VERSION "1.0.x-173216:1"

NS_ :

BS_:

BU_: PropulsionBatteryCharger iBooster TCM HCU STEERING_CONTROLLER BMS Traction_Motor_Controller
VAL_TABLE_ BCH1_PWR_LINE_State 3 "Not_Available" 2 "Error" 1 "Connected" 0 "Disconnected" ;
VAL_TABLE_ BCH1_ChargerState 3 "Disabled" 2 "Stand_by" 1 "Charging" 0 "Battery Disconnected" ;
VAL_TABLE_ Sendyne_Data 128 "Temperature_mC" 98 "Voltage_2_V" 97 "Voltage_1_V" 96 "Voltage_0_V" 65 "Coulomb_Count_High" 64 "Coulomb_Count_Low" 32 "Current_A" ;
VAL_TABLE_ BMS_Fault_State 1 "Active" 0 "- - - - - -" ;
VAL_TABLE_ BMS_MODE 2 "DRIVE" 1 "CHARGE" 0 "IDLE" ;

BO_ 3221225472 VECTOR__INDEPENDENT_SIG_MSG: 0 Vector__XXX
 SG_ BatteryOverVoltageAlarm : 0|1@1+ (1,0) [0|1] "" Vector__XXX
 SG_ WATT_pEPCU_2_Check_Sequence : 0|8@1+ (1,0) [0|255] "" Vector__XXX
 SG_ WATT_pEPCU_2_Var_4 : 0|16@1+ (0.1,-32768) [-32768|31488] "RPM" Vector__XXX
 SG_ WATT_pEPCU_2_Var_3 : 0|16@1+ (0.1,-3276.8) [-3276.8|3148.7] "Nm" Vector__XXX
 SG_ WATT_pEPCU_2_Var_2 : 0|16@1+ (0.1,-3276.8) [-3276.8|3148.7] "Nm" Vector__XXX
 SG_ WATT_pEPCU_2_Var_1 : 0|4@1+ (1,0) [0|15] "" Vector__XXX
 SG_ WATT_pEPCU_2_cntrl : 0|4@1+ (1,0) [0|15] "" Vector__XXX
 SG_ Min_Cell_Voltage : 0|16@1+ (0.001,0) [0|65.535] "V" Vector__XXX
 SG_ Min_Cell_Voltage : 0|16@1+ (0.001,0) [0|65.535] "V" Vector__XXX
 SG_ New_Signal_1897 : 0|8@1+ (1,0) [0|0] "" Vector__XXX

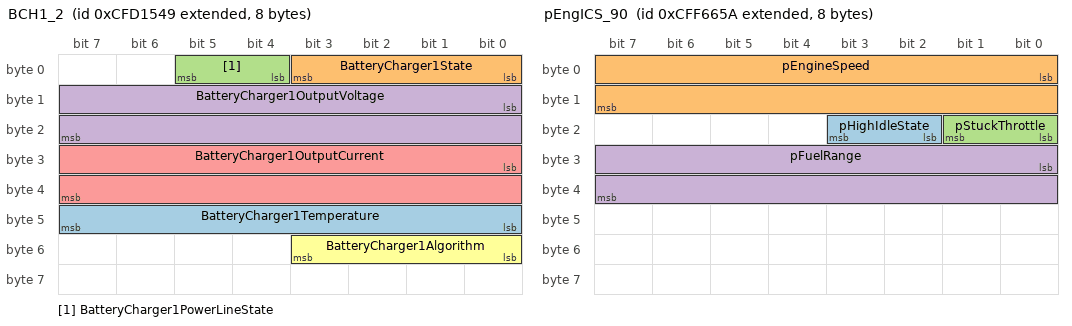
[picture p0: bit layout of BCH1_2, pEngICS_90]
BO_ 2365396297 BCH1_2: 8 Vector__XXX
 SG_ BatteryCharger1Temperature : 40|8@1+ (1,-40) [-40|210] "C" Vector__XXX
 SG_ BatteryCharger1State : 0|4@1+ (1,0) [0|15] "" Vector__XXX
 SG_ BatteryCharger1PowerLineState : 4|2@1+ (1,0) [0|3] "" Vector__XXX
 SG_ BatteryCharger1OutputVoltage : 8|16@1+ (0.05,0) [0|3212.75] "V" Vector__XXX
 SG_ BatteryCharger1OutputCurrent : 24|16@1+ (0.05,-1600) [-1600|1612.75] "A" Vector__XXX
 SG_ BatteryCharger1Algorithm : 48|4@1+ (1,0) [0|15] "" Vector__XXX

BO_ 2316304912 Sendyne_Data: 8 Vector__XXX
 SG_ Sendyne_Type : 0|8@1+ (1,0) [0|255] "" Vector__XXX
 SG_ Sendyne_Data : 15|32@0+ (1E-006,0) [0|4294.967295] "" Vector__XXX

BO_ 2316304913 Sendyne_Request: 1 Vector__XXX
 SG_ Sendyne_Type : 0|8@1+ (1,0) [0|255] "" Vector__XXX

BO_ 2147483941 Traction_Mtr_Ctl_125: 8 Traction_Motor_Controller
 SG_ Torque_Actual_MCU : 16|16@1+ (0.0625,0) [0|4095.9375] "Nm" Vector__XXX
 SG_ Max_Pwr_Lmt_Torque_MCU : 32|16@1+ (0.0625,0) [0|4095.9375] "Nm" Vector__XXX
 SG_ Capacitor_Voltage_MCU : 48|16@1+ (0.0625,0) [0|4095.9375] "V" Vector__XXX

BO_ 2147483940 Traction_Mtr_Ctl_124: 7 Traction_Motor_Controller
 SG_ Stator_Current_MCU : 40|16@1+ (1,0) [0|65535] "A" Vector__XXX
 SG_ Input_Current_MCU : 24|16@1+ (0.0625,0) [0|4095.9375] "A" Vector__XXX

BO_ 2365548122 pEngICS_90: 8 HCU
 SG_ pHighIdleState : 18|2@1+ (1,0) [0|3] "" Vector__XXX
 SG_ pEngineSpeed : 0|16@1+ (1,0) [0|64255] "rpm" Vector__XXX
 SG_ pStuckThrottle : 16|2@1+ (1,0) [0|3] "" Vector__XXX
 SG_ pFuelRange : 24|16@1+ (1,0) [0|64255] "km" Vector__XXX

BO_ 2565866330 EEC2_90: 8 HCU
 SG_ AccelPedalPosition1 : 8|8@1+ (0.4,0) [0|100] "%" Vector__XXX

BO_ 2566889562 BWDevelopmentPGN0_90: 8 HCU
 SG_ pHybridPowertrainSubmode : 2|3@1+ (1,0) [0|0] "1" Vector__XXX
 SG_ pEStopStatus : 0|2@1+ (1,0) [0|0] "1" Vector__XXX

BO_ 2633984602 pDriveSystemStatus_90: 8 HCU
 SG_ pHeatedGripEnable : 48|2@1+ (1,0) [0|3] "" Vector__XXX
 SG_ pSideStandStatus : 36|2@1+ (1,0) [0|3] "" Vector__XXX
 SG_ pTetherSwitchStatus : 46|2@1+ (1,0) [0|3] "" Vector__XXX
 SG_ pLowFuelIndicatorStatus : 10|2@1+ (1,0) [0|3] "" Vector__XXX
 SG_ pOperatorNotInOperatingStation : 38|2@1+ (1,0) [0|3] "" Vector__XXX
 SG_ pParkBrakeIndicatorStatus : 40|3@1+ (1,0) [0|7] "" Vector__XXX
 SG_ pADCRequested : 34|2@1+ (1,0) [0|3] "" Vector__XXX
 SG_ pAWDModeRequested : 32|2@1+ (1,0) [0|3] "" Vector__XXX
 SG_ pRWDModeRequested : 30|2@1+ (1,0) [0|3] "" Vector__XXX
 SG_ pTurfModeRequested : 28|2@1+ (1,0) [0|3] "" Vector__XXX
 SG_ pADCStatus : 0|2@1+ (1,0) [0|3] "" Vector__XXX
 SG_ pTreadleNeutralStatus : 2|2@1+ (1,0) [0|3] "" Vector__XXX
 SG_ pTreadleReverseStatus : 4|2@1+ (1,0) [0|3] "" Vector__XXX
 SG_ pSecurityLightStatus : 6|2@1+ (1,0) [0|3] "" Vector__XXX
 SG_ pHighBeamIndicatorStatus : 8|2@1+ (1,0) [0|3] "" Vector__XXX
 SG_ pHeatedGripsPercentage : 16|8@1+ (0.4,0) [0|100] "%" Vector__XXX
 SG_ pCruiseControlSetStatus : 24|2@1+ (1,0) [0|3] "" Vector__XXX
 SG_ pSeatBeltIndicatorStatus : 12|3@1+ (1,0) [0|7] "" Vector__XXX

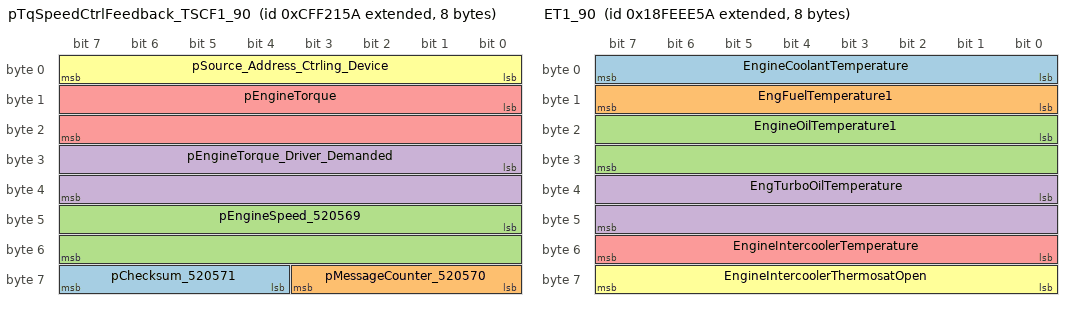
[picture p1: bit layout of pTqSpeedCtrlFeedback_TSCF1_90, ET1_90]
BO_ 2365530458 pTqSpeedCtrlFeedback_TSCF1_90: 8 HCU
 SG_ pChecksum_520571 : 60|4@1+ (1,0) [0|15] "" Vector__XXX
 SG_ pMessageCounter_520570 : 56|4@1+ (1,0) [0|15] "" Vector__XXX
 SG_ pEngineSpeed_520569 : 40|16@1+ (1,0) [0|64255] "rpm" Vector__XXX
 SG_ pEngineTorque_Driver_Demanded : 24|16@1+ (0.03125,0) [0|2047.96875] "Nm" Vector__XXX
 SG_ pEngineTorque : 8|16@1+ (0.03125,0) [0|2047.96875] "Nm" Vector__XXX
 SG_ pSource_Address_Ctrling_Device : 0|8@1+ (1,0) [0|255] "Source Address" Vector__XXX

BO_ 2566843994 ET1_90: 8 HCU
 SG_ EngineCoolantTemperature : 0|8@1+ (1,-40) [-40|210] "°C" Vector__XXX
 SG_ EngFuelTemperature1 : 8|8@1+ (1,-40) [-40|210] "°C" Vector__XXX
 SG_ EngineOilTemperature1 : 16|16@1+ (0.03125,-273) [-273|1734.96875] "°C" Vector__XXX
 SG_ EngTurboOilTemperature : 32|16@1+ (0.03125,-273) [-273|1734.96875] "°C" Vector__XXX
 SG_ EngineIntercoolerTemperature : 48|8@1+ (1,-40) [-40|210] "°C" Vector__XXX
 SG_ EngineIntercoolerThermosatOpen : 56|8@1+ (0.4,0) [0|100] "%" Vector__XXX

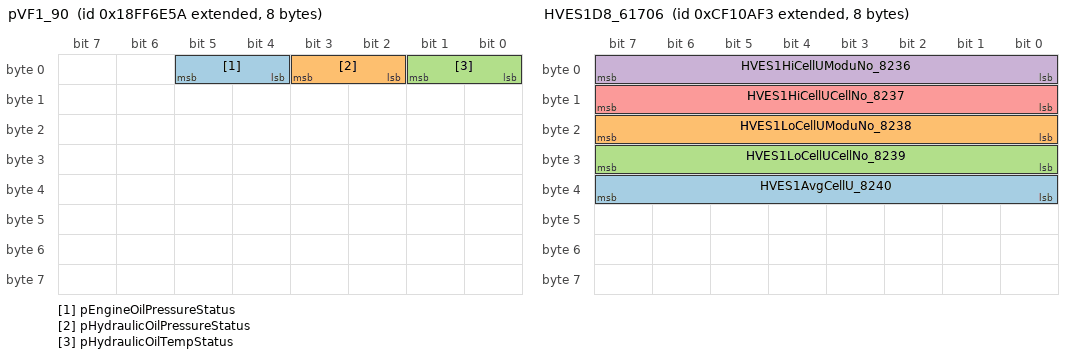
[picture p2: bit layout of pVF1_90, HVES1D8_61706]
BO_ 2566876762 pVF1_90: 8 HCU
 SG_ pEngineOilPressureStatus : 4|2@1+ (1,0) [0|3] "" Vector__XXX
 SG_ pHydraulicOilPressureStatus : 2|2@1+ (1,0) [0|3] "" Vector__XXX
 SG_ pHydraulicOilTempStatus : 0|2@1+ (1,0) [0|3] "" Vector__XXX

BO_ 2364607475 HVES1D9_61707: 8 BMS
 SG_ HVES1LoCellTModuNo_8243 : 16|8@1+ (1,0) [0|250] "count" Vector__XXX
 SG_ HVES1LoCellTCellNo_8244 : 24|8@1+ (1,0) [0|250] "count" Vector__XXX
 SG_ HVES1HiCellTModuNo_8241 : 0|8@1+ (1,0) [0|250] "count" Vector__XXX
 SG_ HVES1HiCellTCellNo_8242 : 8|8@1+ (1,0) [0|250] "count" Vector__XXX

BO_ 2364607219 HVES1D8_61706: 8 BMS
 SG_ HVES1AvgCellU_8240 : 32|8@1+ (1,0) [0|250] "count" Vector__XXX
 SG_ HVES1LoCellUModuNo_8238 : 16|8@1+ (1,0) [0|250] "count" Vector__XXX
 SG_ HVES1LoCellUCellNo_8239 : 24|8@1+ (1,0) [0|250] "count" Vector__XXX
 SG_ HVES1HiCellUModuNo_8236 : 0|8@1+ (1,0) [0|250] "count" Vector__XXX
 SG_ HVES1HiCellUCellNo_8237 : 8|8@1+ (1,0) [0|250] "count" Vector__XXX

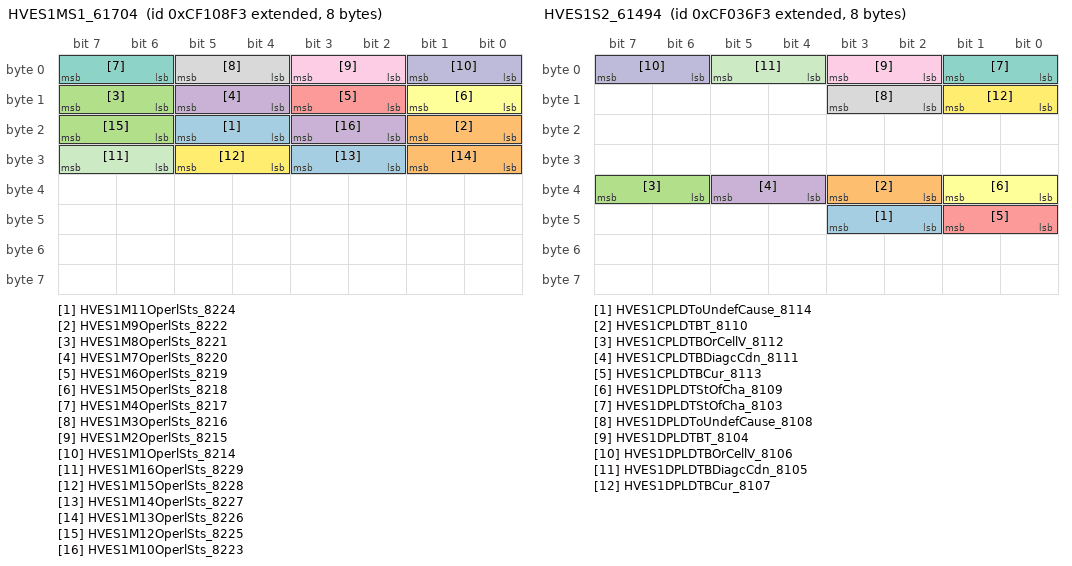
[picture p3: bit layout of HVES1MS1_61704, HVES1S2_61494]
BO_ 2364606707 HVES1MS1_61704: 8 BMS
 SG_ HVES1M11OperlSts_8224 : 20|2@1+ (1,0) [0|3] "bit" Vector__XXX
 SG_ HVES1M9OperlSts_8222 : 16|2@1+ (1,0) [0|3] "bit" Vector__XXX
 SG_ HVES1M8OperlSts_8221 : 14|2@1+ (1,0) [0|3] "bit" Vector__XXX
 SG_ HVES1M7OperlSts_8220 : 12|2@1+ (1,0) [0|3] "bit" Vector__XXX
 SG_ HVES1M6OperlSts_8219 : 10|2@1+ (1,0) [0|3] "bit" Vector__XXX
 SG_ HVES1M5OperlSts_8218 : 8|2@1+ (1,0) [0|3] "bit" Vector__XXX
 SG_ HVES1M4OperlSts_8217 : 6|2@1+ (1,0) [0|3] "bit" Vector__XXX
 SG_ HVES1M3OperlSts_8216 : 4|2@1+ (1,0) [0|3] "bit" Vector__XXX
 SG_ HVES1M2OperlSts_8215 : 2|2@1+ (1,0) [0|3] "bit" Vector__XXX
 SG_ HVES1M1OperlSts_8214 : 0|2@1+ (1,0) [0|3] "bit" Vector__XXX
 SG_ HVES1M16OperlSts_8229 : 30|2@1+ (1,0) [0|3] "bit" Vector__XXX
 SG_ HVES1M15OperlSts_8228 : 28|2@1+ (1,0) [0|3] "bit" Vector__XXX
 SG_ HVES1M14OperlSts_8227 : 26|2@1+ (1,0) [0|3] "bit" Vector__XXX
 SG_ HVES1M13OperlSts_8226 : 24|2@1+ (1,0) [0|3] "bit" Vector__XXX
 SG_ HVES1M12OperlSts_8225 : 22|2@1+ (1,0) [0|3] "bit" Vector__XXX
 SG_ HVES1M10OperlSts_8223 : 18|2@1+ (1,0) [0|3] "bit" Vector__XXX

BO_ 2364552947 HVES1S2_61494: 8 BMS
 SG_ HVES1CPLDToUndefCause_8114 : 42|2@1+ (1,0) [0|3] "bit" Vector__XXX
 SG_ HVES1CPLDTBT_8110 : 34|2@1+ (1,0) [0|3] "bit" Vector__XXX
 SG_ HVES1CPLDTBOrCellV_8112 : 38|2@1+ (1,0) [0|3] "bit" Vector__XXX
 SG_ HVES1CPLDTBDiagcCdn_8111 : 36|2@1+ (1,0) [0|3] "bit" Vector__XXX
 SG_ HVES1CPLDTBCur_8113 : 40|2@1+ (1,0) [0|3] "bit" Vector__XXX
 SG_ HVES1DPLDTStOfCha_8109 : 32|2@1+ (1,0) [0|3] "bit" Vector__XXX
 SG_ HVES1DPLDTStOfCha_8103 : 0|2@1+ (1,0) [0|3] "bit" Vector__XXX
 SG_ HVES1DPLDToUndefCause_8108 : 10|2@1+ (1,0) [0|3] "bit" Vector__XXX
 SG_ HVES1DPLDTBT_8104 : 2|2@1+ (1,0) [0|3] "bit" Vector__XXX
 SG_ HVES1DPLDTBOrCellV_8106 : 6|2@1+ (1,0) [0|3] "bit" Vector__XXX
 SG_ HVES1DPLDTBDiagcCdn_8105 : 4|2@1+ (1,0) [0|3] "bit" Vector__XXX
 SG_ HVES1DPLDTBCur_8107 : 8|2@1+ (1,0) [0|3] "bit" Vector__XXX

BO_ 2633785075 HVES1HIST_64606: 8 BMS
 SG_ HVES1TotEgyThput_8211 : 24|32@1+ (100,0) [0|429496729500] "Watt-hour" Vector__XXX
 SG_ HVES1TotAccumCha_8212 : 56|32@1+ (100,0) [0|429496729500] "Ah" Vector__XXX
 SG_ HVES1StOfHealth_8121 : 0|8@1+ (0.02044,0) [0|5.2122] "V" Vector__XXX
 SG_ HVES1CtorOpenUndLoa_8122 : 8|16@1+ (1,0) [0|64255] "count" Vector__XXX

BO_ 2566675955 HVES1CFG_64605: 8 BMS
 SG_ HVES1RecomMinSOC_8118 : 48|16@1+ (0.0015625,0) [0|102.3984375] "%" Vector__XXX
 SG_ HVES1RecomMinOpergV_8116 : 16|16@1+ (0.05,0) [0|3276.75] "V" Vector__XXX
 SG_ HVES1RecomMinOpergT_8208 : 96|16@1+ (0.03125,-273) [-273|1774.96875] "deg C" Vector__XXX
 SG_ HVES1RecomMaxSOC_8119 : 64|16@1+ (0.0015625,0) [0|102.3984375] "%" Vector__XXX
 SG_ HVES1RecomMaxOpergV_8117 : 32|16@1+ (0.05,0) [0|3276.75] "V" Vector__XXX
 SG_ HVES1RecomMaxOpergT_8120 : 80|16@1+ (0.03125,-273) [-273|1774.96875] "deg C" Vector__XXX
 SG_ HVES1NomVoltage_8115 : 0|16@1+ (0.05,0) [0|3276.75] "V" Vector__XXX
 SG_ HVES1CellMinVLim_8210 : 120|8@1+ (0.02044,0) [0|5.2122] "V" Vector__XXX
 SG_ HVES1CellMaxVLim_8209 : 112|8@1+ (0.02044,0) [0|5.2122] "V" Vector__XXX

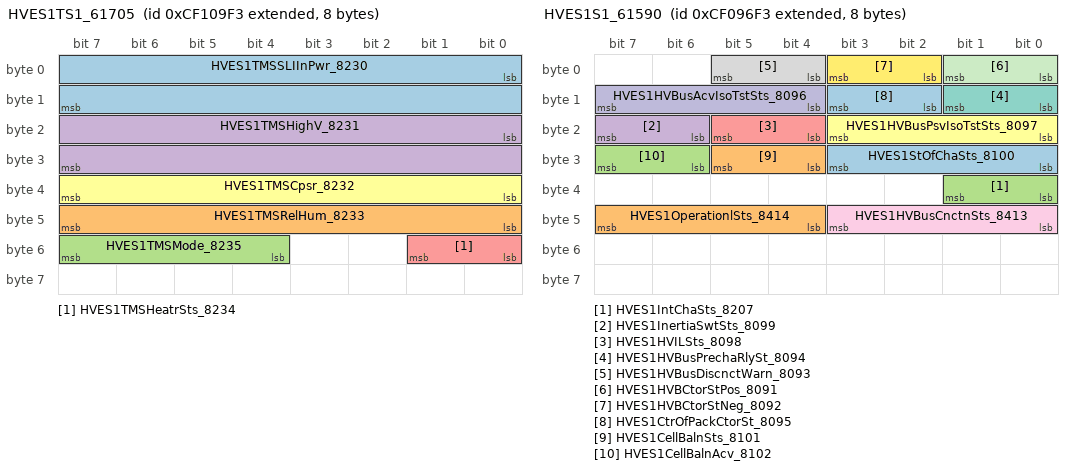
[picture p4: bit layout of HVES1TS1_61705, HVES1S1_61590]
BO_ 2364606963 HVES1TS1_61705: 8 BMS
 SG_ HVES1TMSSLIInPwr_8230 : 0|16@1+ (0.5,0) [0|32767.5] "W" Vector__XXX
 SG_ HVES1TMSRelHum_8233 : 40|8@1+ (0.4,0) [0|102] "%" Vector__XXX
 SG_ HVES1TMSMode_8235 : 52|4@1+ (1,0) [0|15] "bits" Vector__XXX
 SG_ HVES1TMSHighV_8231 : 16|16@1+ (0.5,0) [0|32767.5] "W" Vector__XXX
 SG_ HVES1TMSHeatrSts_8234 : 48|2@1+ (1,0) [0|3] "bits" Vector__XXX
 SG_ HVES1TMSCpsr_8232 : 32|8@1+ (32,0) [0|8160] "rpm" Vector__XXX

BO_ 2364580083 HVES1D7_61600: 8 BMS
 SG_ HVES1MaxChaVLim_8090 : 48|16@1+ (0.05,0) [0|3276.75] "V" Vector__XXX
 SG_ HVES1DischaEgyCp_8205 : 0|24@1+ (0.001,0) [0|16777.215] "kWh" Vector__XXX
 SG_ HVES1ChaEgyCp_8206 : 24|24@1+ (0.001,0) [0|16777.215] "kWh" Vector__XXX

BO_ 2364577523 HVES1S1_61590: 8 BMS
 SG_ HVES1StOfChaSts_8100 : 24|4@1+ (1,0) [0|15] "bits" Vector__XXX
 SG_ HVES1OperationlSts_8414 : 44|4@1+ (1,0) [0|15] "bit" Vector__XXX
 SG_ HVES1IntChaSts_8207 : 32|2@1+ (1,0) [0|3] "bits" Vector__XXX
 SG_ HVES1InertiaSwtSts_8099 : 22|2@1+ (1,0) [0|3] "bits" Vector__XXX
 SG_ HVES1HVILSts_8098 : 20|2@1+ (1,0) [0|3] "bits" Vector__XXX
 SG_ HVES1HVBusPsvIsoTstSts_8097 : 16|4@1+ (1,0) [0|15] "bits" Vector__XXX
 SG_ HVES1HVBusPrechaRlySt_8094 : 8|2@1+ (1,0) [0|3] "bits" Vector__XXX
 SG_ HVES1HVBusDiscnctWarn_8093 : 4|2@1+ (1,0) [0|15] "bits" Vector__XXX
 SG_ HVES1HVBusCnctnSts_8413 : 40|4@1+ (1,0) [0|15] "bits" Vector__XXX
 SG_ HVES1HVBusAcvIsoTstSts_8096 : 12|4@1+ (1,0) [0|15] "bits" Vector__XXX
 SG_ HVES1HVBCtorStPos_8091 : 0|2@1+ (1,0) [0|3] "bit" Vector__XXX
 SG_ HVES1HVBCtorStNeg_8092 : 2|2@1+ (1,0) [0|3] "bit" Vector__XXX
 SG_ HVES1CtrOfPackCtorSt_8095 : 10|2@1+ (1,0) [0|3] "bits" Vector__XXX
 SG_ HVES1CellBalnSts_8101 : 28|2@1+ (1,0) [0|3] "bit" Vector__XXX
 SG_ HVES1CellBalnAcv_8102 : 30|2@1+ (1,0) [0|3] "bit" Vector__XXX

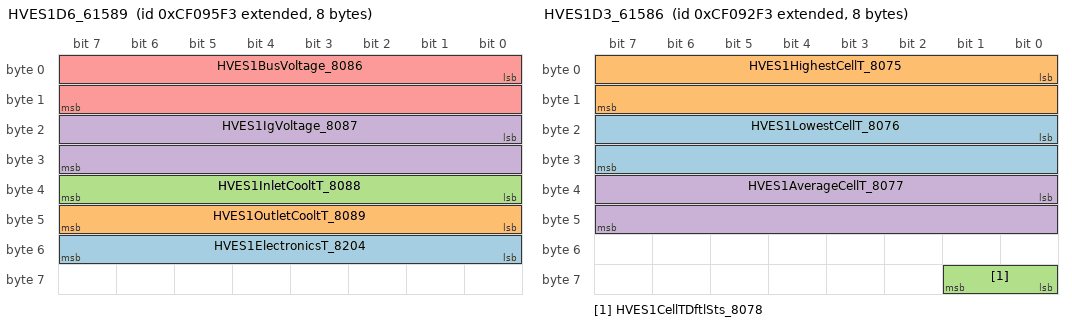
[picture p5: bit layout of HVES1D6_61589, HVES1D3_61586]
BO_ 2364577267 HVES1D6_61589: 8 BMS
 SG_ HVES1ElectronicsT_8204 : 48|8@1+ (1,-40) [-40|215] "deg C" Vector__XXX
 SG_ HVES1OutletCooltT_8089 : 40|8@1+ (1,-40) [-40|215] "deg C" Vector__XXX
 SG_ HVES1InletCooltT_8088 : 32|8@1+ (1,-40) [-40|215] "deg C" Vector__XXX
 SG_ HVES1IgVoltage_8087 : 16|16@1+ (0.01,0) [0|655.35] "V" Vector__XXX
 SG_ HVES1BusVoltage_8086 : 0|16@1+ (0.05,0) [0|3276.75] "V" Vector__XXX

BO_ 2364577011 HVES1D4_61588: 8 BMS
 SG_ HVES1MinCellStOCha_8084 : 32|16@1+ (0.0015625,0) [0|102.3984375] "%" Vector__XXX
 SG_ HVES1MaxCellStOCha_8085 : 48|16@1+ (0.0015625,0) [0|102.3984375] "%" Vector__XXX
 SG_ HVES1DchaCurLim_8082 : 0|16@1+ (0.05,-1600) [-1600|1676.75] "A" Vector__XXX
 SG_ HVES1ChaCurLim_8083 : 16|16@1+ (0.05,-1600) [-1600|1676.75] "A" Vector__XXX

BO_ 2364576755 HVES1D4_61587: 8 BMS
 SG_ HVES1DischargeCap_8079 : 0|16@1+ (0.01,0) [0|655.35] "Ah" Vector__XXX
 SG_ HVES1ChargeCap_8080 : 16|16@1+ (0.01,0) [0|655.35] "Ah" Vector__XXX
 SG_ HVES1CellBalnCt_8081 : 32|16@1+ (1,0) [0|65535] "count" Vector__XXX

BO_ 2364576499 HVES1D3_61586: 8 BMS
 SG_ HVES1LowestCellT_8076 : 16|16@1+ (0.03125,-273) [-273|1774.96875] "degrees C" Vector__XXX
 SG_ HVES1HighestCellT_8075 : 0|16@1+ (0.03125,-273) [-273|1774.96875] "degrees C" Vector__XXX
 SG_ HVES1CellTDftlSts_8078 : 56|2@1+ (1,0) [0|3] "bits" Vector__XXX
 SG_ HVES1AverageCellT_8077 : 32|16@1+ (0.03125,-273) [-273|1774.96875] "degrees C" Vector__XXX

BO_ 2364576243 HVES1D2_61585: 8 BMS
 SG_ HVES1LowCellVolt_5923 : 32|16@1+ (0.001,0) [0|65.535] "V" Vector__XXX
 SG_ HVES1HiCellVolt_5922 : 16|16@1+ (0.001,0) [0|65.535] "V" Vector__XXX
 SG_ HVES1FastUpdStOCh_5921 : 0|16@1+ (0.0015625,0) [0|102.3984375] "%" Vector__XXX
 SG_ HVES1CellVoltDftlSts_5924 : 56|4@1+ (1,0) [0|15] "bot" Vector__XXX

BO_ 2364575987 HVES1D1_61584: 8 BMS
 SG_ HVES1VoltageLevel_5919 : 32|16@1+ (0.05,0) [0|3276.75] "V" Vector__XXX
 SG_ HVES1Current_5920 : 48|16@1+ (0.05,-1600) [-1600|1676.75] "A" Vector__XXX
 SG_ HVES1AvlChPwr_5918 : 16|16@1+ (0.05,0) [0|3276.75] "kW" Vector__XXX
 SG_ HVES1AvlDchaPwr_5917 : 0|16@1+ (0.05,0) [0|3276.75] "kW" Vector__XXX

BO_ 2230362355 BMCVL: 8 Vector__XXX
 SG_ HVES1_Max_Charge_Voltage_Limit : 48|16@1+ (0.05,0) [0|3212.75] "V"  PropulsionBatteryCharger

BO_ 2230359283 BCCL: 8 Vector__XXX
 SG_ HVES1_Charge_Current_Limit : 16|16@1+ (0.05,-1600) [-1600|1612.75] "A"  PropulsionBatteryCharger

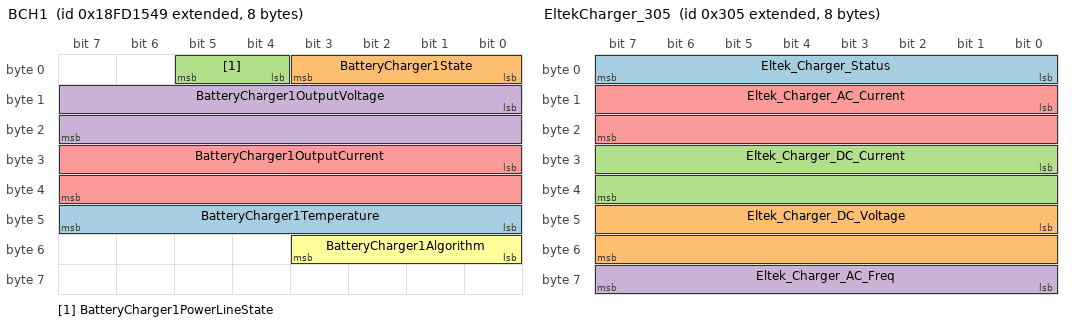
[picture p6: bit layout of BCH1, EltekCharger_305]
BO_ 2566722889 BCH1: 8 PropulsionBatteryCharger
 SG_ BatteryCharger1Temperature : 40|8@1+ (1,-40) [-40|210] "C" Vector__XXX
 SG_ BatteryCharger1State : 0|4@1+ (1,0) [0|15] "" Vector__XXX
 SG_ BatteryCharger1PowerLineState : 4|2@1+ (1,0) [0|3] "" Vector__XXX
 SG_ BatteryCharger1OutputVoltage : 8|16@1+ (0.05,0) [0|3212.75] "V" Vector__XXX
 SG_ BatteryCharger1OutputCurrent : 24|16@1+ (0.05,-1600) [-1600|1612.75] "A" Vector__XXX
 SG_ BatteryCharger1Algorithm : 48|4@1+ (1,0) [0|15] "" Vector__XXX

BO_ 2147484421 EltekCharger_305: 8 Vector__XXX
 SG_ Eltek_Charger_Status : 0|8@1+ (1,0) [0|255] "Mode" Vector__XXX
 SG_ Eltek_Charger_DC_Voltage : 40|16@1+ (0.1,0) [0|6553.5] "V" Vector__XXX
 SG_ Eltek_Charger_DC_Current : 24|16@1+ (0.1,0) [0|6553.5] "A" Vector__XXX
 SG_ Eltek_Charger_AC_Freq : 63|8@0+ (1,0) [0|255] "Hz" Vector__XXX
 SG_ Eltek_Charger_AC_Current : 8|16@1+ (0.1,0) [0|6553.5] "A" Vector__XXX

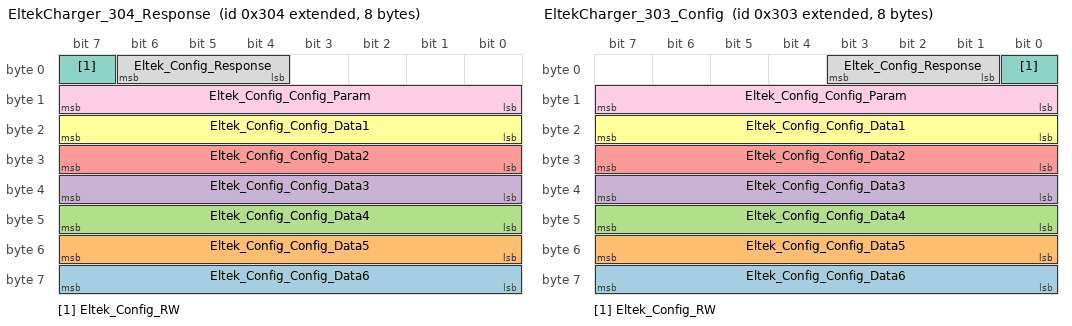
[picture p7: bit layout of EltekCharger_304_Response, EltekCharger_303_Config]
BO_ 2147484420 EltekCharger_304_Response: 8 Vector__XXX
 SG_ Eltek_Config_Config_Data6 : 63|8@0+ (1,0) [0|0] "" Vector__XXX
 SG_ Eltek_Config_Config_Data5 : 55|8@0+ (1,0) [0|0] "" Vector__XXX
 SG_ Eltek_Config_Config_Data4 : 47|8@0+ (1,0) [0|0] "" Vector__XXX
 SG_ Eltek_Config_Config_Data3 : 39|8@0+ (1,0) [0|0] "" Vector__XXX
 SG_ Eltek_Config_Config_Data2 : 31|8@0+ (1,0) [0|0] "" Vector__XXX
 SG_ Eltek_Config_Config_Data1 : 23|8@0+ (1,0) [0|0] "" Vector__XXX
 SG_ Eltek_Config_RW : 7|1@0+ (1,0) [0|0] "" Vector__XXX
 SG_ Eltek_Config_Response : 6|3@0+ (1,0) [0|0] "" Vector__XXX
 SG_ Eltek_Config_Config_Param : 15|8@0+ (1,0) [0|0] "" Vector__XXX

BO_ 2147484419 EltekCharger_303_Config: 8 Vector__XXX
 SG_ Eltek_Config_Config_Data6 : 63|8@0+ (1,0) [0|0] "" Vector__XXX
 SG_ Eltek_Config_Config_Data5 : 55|8@0+ (1,0) [0|0] "" Vector__XXX
 SG_ Eltek_Config_Config_Data4 : 47|8@0+ (1,0) [0|0] "" Vector__XXX
 SG_ Eltek_Config_Config_Data3 : 39|8@0+ (1,0) [0|0] "" Vector__XXX
 SG_ Eltek_Config_Config_Data2 : 31|8@0+ (1,0) [0|0] "" Vector__XXX
 SG_ Eltek_Config_Config_Data1 : 23|8@0+ (1,0) [0|0] "" Vector__XXX
 SG_ Eltek_Config_RW : 0|1@0+ (1,0) [0|0] "" Vector__XXX
 SG_ Eltek_Config_Response : 3|3@0+ (1,0) [0|0] "" Vector__XXX
 SG_ Eltek_Config_Config_Param : 15|8@0+ (1,0) [0|0] "" Vector__XXX

BO_ 2147484424 EltekCharger_308: 8 Vector__XXX
 SG_ Eltek_Charger_Serial_Number : 7|48@0+ (1,0) [0|2.8147497671066E+014] "" Vector__XXX
 SG_ Eltek_Charger_BaseCANID : 55|16@0+ (1,0) [0|65535] "" Vector__XXX

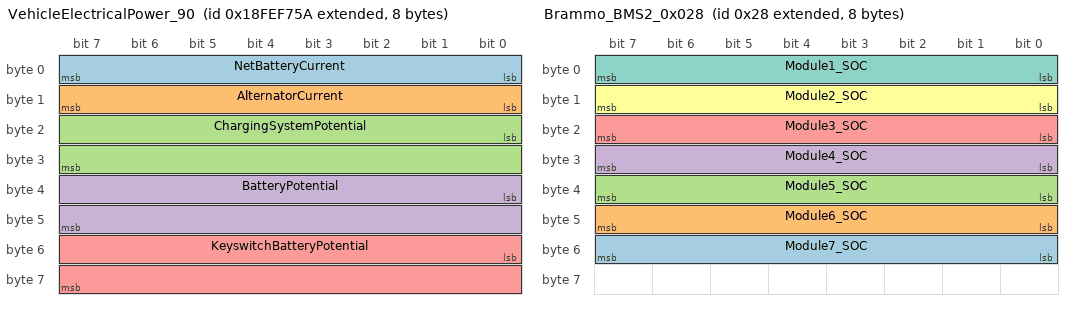
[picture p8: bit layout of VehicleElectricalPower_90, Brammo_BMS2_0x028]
BO_ 2566846298 VehicleElectricalPower_90: 8 HCU
 SG_ NetBatteryCurrent : 0|8@1+ (1,-125) [-125|125] "A" Vector__XXX
 SG_ AlternatorCurrent : 8|8@1+ (1,0) [0|250] "A" Vector__XXX
 SG_ ChargingSystemPotential : 16|16@1+ (0.05,0) [0|3212.75] "V" Vector__XXX
 SG_ BatteryPotential : 32|16@1+ (0.05,0) [0|3212.75] "V" Vector__XXX
 SG_ KeyswitchBatteryPotential : 48|16@1+ (0.05,0) [0|3212.75] "V" Vector__XXX

BO_ 2147483688 Brammo_BMS2_0x028: 8 Vector__XXX
 SG_ Module7_SOC : 48|8@1+ (0.3921568627451,0) [0|100] "%" Vector__XXX
 SG_ Module6_SOC : 40|8@1+ (0.3921568627451,0) [0|100] "%" Vector__XXX
 SG_ Module5_SOC : 32|8@1+ (0.3921568627451,0) [0|100] "%" Vector__XXX
 SG_ Module4_SOC : 24|8@1+ (0.3921568627451,0) [0|100] "%" Vector__XXX
 SG_ Module3_SOC : 16|8@1+ (0.3921568627451,0) [0|100] "%" Vector__XXX
 SG_ Module2_SOC : 8|8@1+ (0.3921568627451,0) [0|100] "%" Vector__XXX
 SG_ Module1_SOC : 0|8@1+ (0.3921568627451,0) [0|100] "%" Vector__XXX

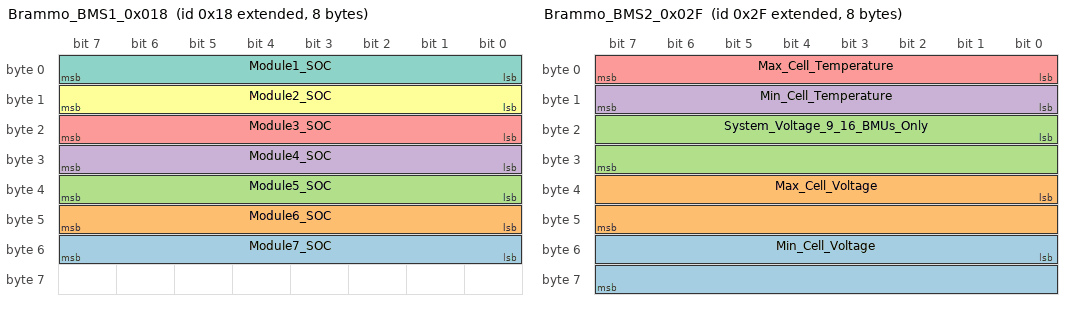
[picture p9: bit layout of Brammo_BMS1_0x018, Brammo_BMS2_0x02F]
BO_ 2147483672 Brammo_BMS1_0x018: 8 BMS
 SG_ Module7_SOC : 48|8@1+ (0.3921568627451,0) [0|100] "%" Vector__XXX
 SG_ Module6_SOC : 40|8@1+ (0.3921568627451,0) [0|100] "%" Vector__XXX
 SG_ Module5_SOC : 32|8@1+ (0.3921568627451,0) [0|100] "%" Vector__XXX
 SG_ Module4_SOC : 24|8@1+ (0.3921568627451,0) [0|100] "%" Vector__XXX
 SG_ Module3_SOC : 16|8@1+ (0.3921568627451,0) [0|100] "%" Vector__XXX
 SG_ Module2_SOC : 8|8@1+ (0.3921568627451,0) [0|100] "%" Vector__XXX
 SG_ Module1_SOC : 0|8@1+ (0.3921568627451,0) [0|100] "%" Vector__XXX

BO_ 2147483695 Brammo_BMS2_0x02F: 8 Vector__XXX
 SG_ Min_Cell_Voltage : 48|16@1+ (0.001,0) [0|65.535] "V" Vector__XXX
 SG_ Max_Cell_Voltage : 32|16@1+ (0.001,0) [0|65.535] "V" Vector__XXX
 SG_ System_Voltage_9_16_BMUs_Only : 16|16@1+ (1,0) [0|65535] "V" Vector__XXX
 SG_ Min_Cell_Temperature : 8|8@1+ (1,-40) [-40|215] "C" Vector__XXX
 SG_ Max_Cell_Temperature : 0|8@1+ (1,-40) [-40|215] "C" Vector__XXX

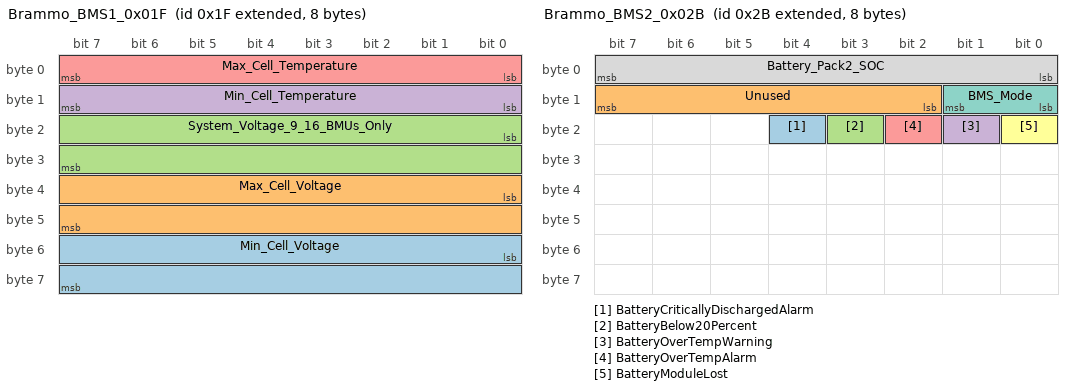
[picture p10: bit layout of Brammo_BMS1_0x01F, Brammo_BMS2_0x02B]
BO_ 2147483679 Brammo_BMS1_0x01F: 8 BMS
 SG_ Min_Cell_Voltage : 48|16@1+ (0.001,0) [0|65.535] "V" Vector__XXX
 SG_ Max_Cell_Voltage : 32|16@1+ (0.001,0) [0|65.535] "V" Vector__XXX
 SG_ System_Voltage_9_16_BMUs_Only : 16|16@1+ (1,0) [0|65535] "V" Vector__XXX
 SG_ Min_Cell_Temperature : 8|8@1+ (1,-40) [-40|215] "C" Vector__XXX
 SG_ Max_Cell_Temperature : 0|8@1+ (1,-40) [-40|215] "C" Vector__XXX

BO_ 2147483691 Brammo_BMS2_0x02B: 8 Vector__XXX
 SG_ BatteryCriticallyDischargedAlarm : 20|1@1+ (1,0) [0|1] "" Vector__XXX
 SG_ Unused : 10|6@1+ (1,0) [0|0] "" Vector__XXX
 SG_ BatteryBelow20Percent : 19|1@1+ (1,0) [0|1] "" Vector__XXX
 SG_ BatteryOverTempWarning : 17|1@1+ (1,0) [0|1] "" Vector__XXX
 SG_ BatteryOverTempAlarm : 18|1@1+ (1,0) [0|1] "" Vector__XXX
 SG_ BatteryModuleLost : 16|1@1+ (1,0) [0|1] "" Vector__XXX
 SG_ BMS_Mode : 8|2@1+ (1,0) [0|2] "Mode" Vector__XXX
 SG_ Battery_Pack2_SOC : 0|8@1+ (1,0) [0|100] "%" Vector__XXX

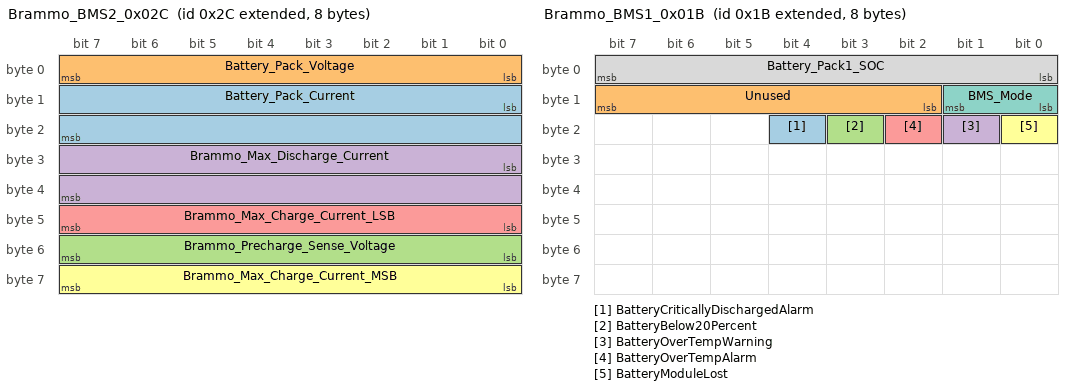
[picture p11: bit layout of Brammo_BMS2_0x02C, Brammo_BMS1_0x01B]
BO_ 2147483692 Brammo_BMS2_0x02C: 8 Vector__XXX
 SG_ Battery_Pack_Current : 8|16@1+ (1,-32768) [-32768|32767] "A" Vector__XXX
 SG_ Battery_Pack_Voltage : 0|8@1+ (1,0) [0|255] "V" Vector__XXX
 SG_ Brammo_Precharge_Sense_Voltage : 48|8@1+ (1,0) [0|255] "V" Vector__XXX
 SG_ Brammo_Max_Discharge_Current : 24|16@1+ (1,0) [0|65535] "A" Vector__XXX
 SG_ Brammo_Max_Charge_Current_LSB : 40|8@1+ (1,0) [0|0] "A" Vector__XXX
 SG_ Brammo_Max_Charge_Current_MSB : 56|8@1+ (1,0) [0|0] "A" Vector__XXX

BO_ 2147483675 Brammo_BMS1_0x01B: 8 BMS
 SG_ BatteryCriticallyDischargedAlarm : 20|1@1+ (1,0) [0|1] "" Vector__XXX
 SG_ Unused : 10|6@1+ (1,0) [0|0] "" Vector__XXX
 SG_ BatteryBelow20Percent : 19|1@1+ (1,0) [0|1] "" Vector__XXX
 SG_ BatteryOverTempWarning : 17|1@1+ (1,0) [0|1] "" Vector__XXX
 SG_ BatteryOverTempAlarm : 18|1@1+ (1,0) [0|1] "" Vector__XXX
 SG_ BatteryModuleLost : 16|1@1+ (1,0) [0|1] "" Vector__XXX
 SG_ BMS_Mode : 8|2@1+ (1,0) [0|2] "Mode" Vector__XXX
 SG_ Battery_Pack1_SOC : 0|8@1+ (1,0) [0|100] "%" Vector__XXX

BO_ 2566885722 RF3_RemoteFeedback3_5A: 8 HCU
 SG_ PowertrainMode : 0|4@1+ (1,0) [0|0] "" Vector__XXX

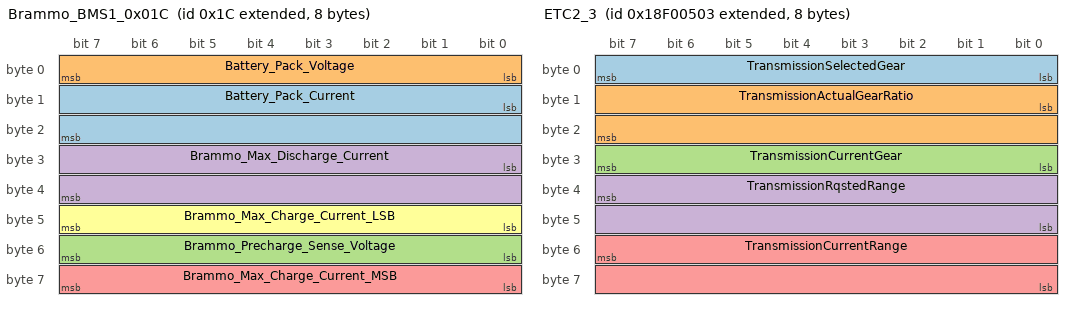
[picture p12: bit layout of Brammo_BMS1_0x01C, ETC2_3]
BO_ 2147483676 Brammo_BMS1_0x01C: 8 BMS
 SG_ Battery_Pack_Current : 8|16@1+ (1,-32768) [-32768|32767] "A" Vector__XXX
 SG_ Battery_Pack_Voltage : 0|8@1+ (1,0) [0|255] "V" Vector__XXX
 SG_ Brammo_Precharge_Sense_Voltage : 48|8@1+ (1,0) [0|255] "V" Vector__XXX
 SG_ Brammo_Max_Discharge_Current : 24|16@1+ (1,0) [0|65535] "A" Vector__XXX
 SG_ Brammo_Max_Charge_Current_MSB : 56|8@1+ (1,0) [0|0] "A" Vector__XXX
 SG_ Brammo_Max_Charge_Current_LSB : 40|8@1+ (1,0) [0|0] "A" Vector__XXX

BO_ 2566841434 SHUTDN_5A: 8 HCU
 SG_ Engine_Wait_to_Start_Lamp : 24|2@1+ (1,0) [0|0] "" Vector__XXX

BO_ 2566841598 SHUTDN: 8 Vector__XXX
 SG_ Engine_Wait_to_Start_Lamp : 24|2@1+ (1,0) [0|0] "" Vector__XXX

BO_ 2348941146 TC1_5A: 8 HCU
 SG_ TrsmGearShiftInhibitReq : 0|2@1+ (1,0) [0|0] "" Vector__XXX
 SG_ TransmissionRequestedGear : 16|8@1+ (1,0) [0|0] "" Vector__XXX

BO_ 2348941059 TC1_3: 8 TCM
 SG_ TrsmGearShiftInhibitReq : 0|2@1+ (1,0) [0|0] "" Vector__XXX
 SG_ TransmissionRequestedGear : 16|8@1+ (1,0) [0|0] "" Vector__XXX

BO_ 2566880525 RBC1_D: 8 iBooster
 SG_ MessageCounter_65397 : 56|4@1+ (1,0) [0|0] "" Vector__XXX
 SG_ MessageChecksum : 60|4@1+ (1,0) [0|15] "" Vector__XXX
 SG_ NormalizedServiceBrakePressure : 8|8@1+ (0.4,0) [0|0] "%" Vector__XXX

BO_ 2566844762 CruiseControlVehSpeed_5A: 8 HCU
 SG_ TwoSpeedAxleSwitch : 0|2@1+ (1,0) [0|3] "" Vector__XXX
 SG_ ParkingBrakeSwitch : 2|2@1+ (1,0) [0|3] "" Vector__XXX
 SG_ Wheel_BasedVehicleSpeed : 8|16@1+ (0.00390625,0) [0|251] "kph" Vector__XXX
 SG_ CruiseCtrlActive : 24|2@1+ (1,0) [0|3] "" Vector__XXX
 SG_ CruiseCtrlEnableSwitch : 26|2@1+ (1,0) [0|3] "" Vector__XXX
 SG_ BrakeSwitch : 28|2@1+ (1,0) [0|3] "" Vector__XXX
 SG_ ClutchSwitch : 30|2@1+ (1,0) [0|3] "" Vector__XXX
 SG_ CruiseCtrlSetSwitch : 32|2@1+ (1,0) [0|3] "" Vector__XXX
 SG_ CruiseCtrlCoastSwitch : 34|2@1+ (1,0) [0|3] "" Vector__XXX
 SG_ CruiseCtrlResumeSwitch : 36|2@1+ (1,0) [0|3] "" Vector__XXX
 SG_ CruiseCtrlAccelerateSwitch : 38|2@1+ (1,0) [0|3] "" Vector__XXX
 SG_ CruiseCtrlSetSpeed : 40|8@1+ (1,0) [0|250] "km/h" Vector__XXX
 SG_ pOdometerDriveBit : 6|2@1+ (1,0) [0|3] "" Vector__XXX
 SG_ CruiseCtrlPauseSw : 4|2@1+ (1,0) [0|3] "" Vector__XXX
 SG_ pCCMessageCounter : 52|4@1+ (1,0) [0|15] "" Vector__XXX
 SG_ pCCChecksum : 56|8@1+ (1,0) [0|255] "" Vector__XXX
 SG_ pCruiseEnableStatus : 48|4@1+ (1,0) [0|15] "" Vector__XXX

BO_ 2566844675 CruiseControlVehSpeed_3: 8 TCM
 SG_ TwoSpeedAxleSwitch : 0|2@1+ (1,0) [0|3] "" Vector__XXX
 SG_ ParkingBrakeSwitch : 2|2@1+ (1,0) [0|3] "" Vector__XXX
 SG_ Wheel_BasedVehicleSpeed : 8|16@1+ (0.00390625,0) [0|251] "kph" Vector__XXX
 SG_ CruiseCtrlActive : 24|2@1+ (1,0) [0|3] "" Vector__XXX
 SG_ CruiseCtrlEnableSwitch : 26|2@1+ (1,0) [0|3] "" Vector__XXX
 SG_ BrakeSwitch : 28|2@1+ (1,0) [0|3] "" Vector__XXX
 SG_ ClutchSwitch : 30|2@1+ (1,0) [0|3] "" Vector__XXX
 SG_ CruiseCtrlSetSwitch : 32|2@1+ (1,0) [0|3] "" Vector__XXX
 SG_ CruiseCtrlCoastSwitch : 34|2@1+ (1,0) [0|3] "" Vector__XXX
 SG_ CruiseCtrlResumeSwitch : 36|2@1+ (1,0) [0|3] "" Vector__XXX
 SG_ CruiseCtrlAccelerateSwitch : 38|2@1+ (1,0) [0|3] "" Vector__XXX
 SG_ CruiseCtrlSetSpeed : 40|8@1+ (1,0) [0|250] "km/h" Vector__XXX
 SG_ pOdometerDriveBit : 6|2@1+ (1,0) [0|3] "" Vector__XXX
 SG_ CruiseCtrlPauseSw : 4|2@1+ (1,0) [0|3] "" Vector__XXX
 SG_ pCCMessageCounter : 52|4@1+ (1,0) [0|15] "" Vector__XXX
 SG_ pCCChecksum : 56|8@1+ (1,0) [0|255] "" Vector__XXX
 SG_ pCruiseEnableStatus : 48|4@1+ (1,0) [0|15] "" Vector__XXX

BO_ 2364539395 ElectricTrsmController_1_3: 8 TCM
 SG_ TrsmShiftInProcess : 4|2@1+ (1,0) [0|0] "1" Vector__XXX

BO_ 2565866755 ETC2_3: 8 TCM
 SG_ TransmissionSelectedGear : 0|8@1+ (1,-125) [-125|125] "" Vector__XXX
 SG_ TransmissionActualGearRatio : 8|16@1+ (0.001,0) [0|64.255] "" Vector__XXX
 SG_ TransmissionCurrentGear : 24|8@1+ (1,-125) [-125|125] "" Vector__XXX
 SG_ TransmissionRqstedRange : 39|16@0+ (1,0) [0|65535] "" Vector__XXX
 SG_ TransmissionCurrentRange : 55|16@0+ (1,0) [0|65535] "" Vector__XXX

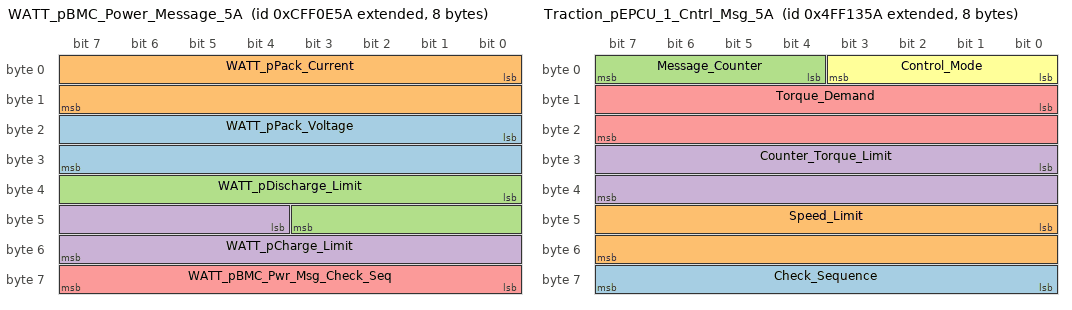
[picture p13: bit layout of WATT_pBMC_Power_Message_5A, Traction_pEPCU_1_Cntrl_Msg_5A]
BO_ 2365525594 WATT_pBMC_Power_Message_5A: 8 HCU
 SG_ WATT_pPack_Voltage : 16|16@1+ (0.05,0) [0|3212.75] "V" Vector__XXX
 SG_ WATT_pPack_Current : 0|16@1+ (0.05,-1600) [-1600|1612.75] "A" Vector__XXX
 SG_ WATT_pDischarge_Limit : 32|12@1+ (0.5,0) [0|2007.5] "A" Vector__XXX
 SG_ WATT_pCharge_Limit : 44|12@1+ (0.5,0) [0|2007.5] "A" Vector__XXX
 SG_ WATT_pBMC_Pwr_Msg_Check_Seq : 56|8@1+ (1,0) [0|255] "" Vector__XXX

BO_ 2231309146 Traction_pEPCU_1_Cntrl_Msg_5A: 8 HCU
 SG_ Check_Sequence : 56|8@1+ (1,0) [0|255] "" Vector__XXX
 SG_ Speed_Limit : 40|16@1+ (1,-32768) [-32768|31488] "RPM" Vector__XXX
 SG_ Message_Counter : 4|4@1+ (1,0) [0|15] "" Vector__XXX
 SG_ Counter_Torque_Limit : 24|16@1+ (0.1,-3276.8) [-3276.8|3148.7] "Nm" Vector__XXX
 SG_ Torque_Demand : 8|16@1+ (0.1,-3276.8) [-3276.8|3148.7] "Nm" Vector__XXX
 SG_ Control_Mode : 0|4@1+ (1,0) [0|15] "" Vector__XXX

BO_ 2432656894 pOperatorSwitchStatus_5A: 8 Vector__XXX
 SG_ pOperatorButton29 : 58|2@1+ (1,0) [0|3] "" Vector__XXX
 SG_ pOperatorButton1 : 0|2@1+ (1,0) [0|3] "" Vector__XXX
 SG_ pOperatorButton2 : 2|2@1+ (1,0) [0|3] "" Vector__XXX
 SG_ pOperatorButton3 : 4|2@1+ (1,0) [0|3] "" Vector__XXX
 SG_ pOperatorButton4 : 6|2@1+ (1,0) [0|3] "" Vector__XXX
 SG_ pOperatorButton5 : 8|2@1+ (1,0) [0|3] "" Vector__XXX
 SG_ pOperatorButton6 : 10|2@1+ (1,0) [0|3] "" Vector__XXX
 SG_ pOperatorButton7 : 12|2@1+ (1,0) [0|3] "" Vector__XXX
 SG_ pOperatorButton8 : 14|2@1+ (1,0) [0|3] "" Vector__XXX
 SG_ pOperatorButton9 : 16|2@1+ (1,0) [0|3] "" Vector__XXX
 SG_ pOperatorButton10 : 18|2@1+ (1,0) [0|3] "" Vector__XXX
 SG_ pOperatorButton11 : 20|2@1+ (1,0) [0|3] "" Vector__XXX
 SG_ pOperatorButton12 : 22|2@1+ (1,0) [0|3] "" Vector__XXX
 SG_ pOperatorButton13 : 24|2@1+ (1,0) [0|3] "" Vector__XXX
 SG_ pOperatorButton14 : 26|2@1+ (1,0) [0|3] "" Vector__XXX
 SG_ pOperatorButton15 : 28|2@1+ (1,0) [0|3] "" Vector__XXX
 SG_ pOperatorButton16 : 30|2@1+ (1,0) [0|3] "" Vector__XXX
 SG_ pOperatorButton17 : 32|2@1+ (1,0) [0|3] "" Vector__XXX
 SG_ pOperatorButton18 : 34|2@1+ (1,0) [0|3] "" Vector__XXX
 SG_ pOperatorButton19 : 36|2@1+ (1,0) [0|3] "" Vector__XXX
 SG_ pOperatorButton20 : 38|2@1+ (1,0) [0|3] "" Vector__XXX
 SG_ pOperatorButton21 : 40|2@1+ (1,0) [0|3] "" Vector__XXX
 SG_ pOperatorButton22 : 42|2@1+ (1,0) [0|3] "" Vector__XXX
 SG_ pOperatorButton23 : 44|2@1+ (1,0) [0|3] "" Vector__XXX
 SG_ pOperatorButton24 : 46|2@1+ (1,0) [0|3] "" Vector__XXX
 SG_ pOperatorButton25 : 48|2@1+ (1,0) [0|3] "" Vector__XXX
 SG_ pOperatorButton26 : 50|2@1+ (1,0) [0|3] "" Vector__XXX
 SG_ pOperatorButton27 : 52|2@1+ (1,0) [0|3] "" Vector__XXX
 SG_ pOperatorButton28 : 54|2@1+ (1,0) [0|3] "" Vector__XXX
 SG_ pSideStandStatus : 56|2@1+ (1,0) [0|3] "" Vector__XXX

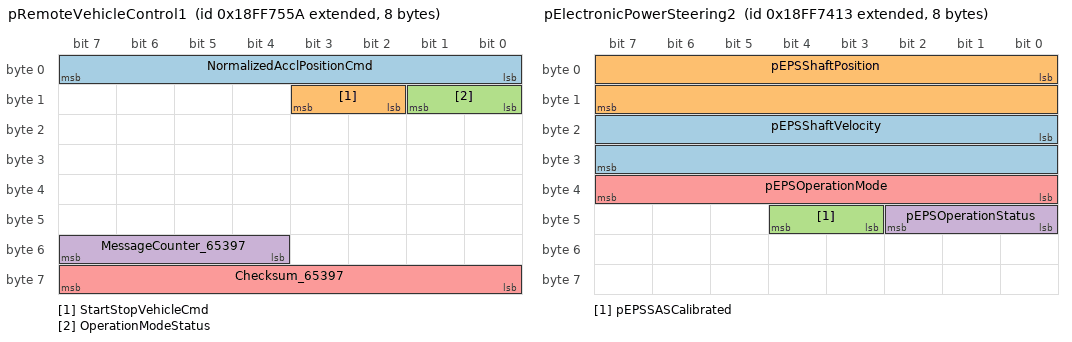
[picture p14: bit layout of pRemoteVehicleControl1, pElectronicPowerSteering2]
BO_ 2566878554 pRemoteVehicleControl1: 8 HCU
 SG_ NormalizedAcclPositionCmd : 0|8@1+ (0.4,0) [0|100] "%" Vector__XXX
 SG_ StartStopVehicleCmd : 10|2@1+ (1,0) [0|0] "" Vector__XXX
 SG_ OperationModeStatus : 8|2@1+ (1,0) [0|0] "" Vector__XXX
 SG_ MessageCounter_65397 : 52|4@1+ (1,0) [0|0] "" Vector__XXX
 SG_ Checksum_65397 : 56|8@1+ (1,0) [0|0] "" Vector__XXX

BO_ 2566878227 pElectronicPowerSteering2: 8 STEERING_CONTROLLER
 SG_ pEPSShaftVelocity : 16|16@1+ (0.1,-3276.5) [-3276.5|3276.5] "degrees per second" Vector__XXX
 SG_ pEPSShaftPosition : 0|16@1+ (0.1,-3276.5) [-3276.5|3276.5] "degrees" Vector__XXX
 SG_ pEPSSASCalibrated : 43|2@1+ (1,0) [0|3] "" Vector__XXX
 SG_ pEPSOperationStatus : 40|3@1+ (1,0) [0|7] "" Vector__XXX
 SG_ pEPSOperationMode : 32|8@1+ (1,0) [0|255] "" Vector__XXX

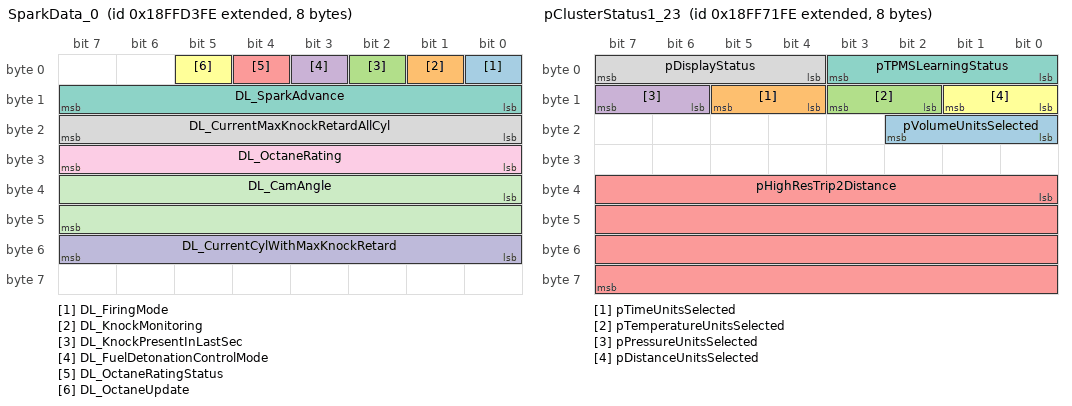
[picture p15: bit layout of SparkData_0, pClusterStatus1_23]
BO_ 2566902782 SparkData_0: 8 Vector__XXX
 SG_ DL_FiringMode : 0|1@1+ (1,0) [0|1] "" Vector__XXX
 SG_ DL_KnockMonitoring : 1|1@1+ (1,0) [0|1] "" Vector__XXX
 SG_ DL_KnockPresentInLastSec : 2|1@1+ (1,0) [0|1] "" Vector__XXX
 SG_ DL_FuelDetonationControlMode : 3|1@1+ (1,0) [0|1] "" Vector__XXX
 SG_ DL_OctaneRatingStatus : 4|1@1+ (1,0) [0|1] "" Vector__XXX
 SG_ DL_OctaneUpdate : 5|1@1+ (1,0) [0|1] "" Vector__XXX
 SG_ DL_SparkAdvance : 8|8@1+ (0.3516,-20) [-20|69.658] "Deg" Vector__XXX
 SG_ DL_CurrentMaxKnockRetardAllCyl : 16|8@1+ (0.08789,0) [0|22.41195] "Deg" Vector__XXX
 SG_ DL_OctaneRating : 24|8@1+ (0.3906,0) [0|99.603] "Cnts" Vector__XXX
 SG_ DL_CurrentCylWithMaxKnockRetard : 48|8@1+ (1,0) [0|255] "Cyl#" Vector__XXX
 SG_ DL_CamAngle : 32|16@1+ (1,0) [0|65535] "" Vector__XXX

BO_ 2566877950 pVT1_0: 8 Vector__XXX
 SG_ pLeftHandGripTemp : 0|8@1+ (1,-40) [-40|210] "deg C" Vector__XXX
 SG_ pRightHandGripTemp : 8|8@1+ (1,-40) [-40|210] "deg C" Vector__XXX

BO_ 2566877694 pClusterStatus1_23: 8 Vector__XXX
 SG_ pVolumeUnitsSelected : 16|3@1+ (1,0) [0|7] "" Vector__XXX
 SG_ pTimeUnitsSelected : 12|2@1+ (1,0) [0|3] "" Vector__XXX
 SG_ pTemperatureUnitsSelected : 10|2@1+ (1,0) [0|3] "" Vector__XXX
 SG_ pPressureUnitsSelected : 14|2@1+ (1,0) [0|3] "" Vector__XXX
 SG_ pHighResTrip2Distance : 32|32@1+ (0.005,0) [0|21055406] "km" Vector__XXX
 SG_ pDistanceUnitsSelected : 8|2@1+ (1,0) [0|3] "" Vector__XXX
 SG_ pTPMSLearningStatus : 0|4@1+ (1,0) [0|15] "" Vector__XXX
 SG_ pDisplayStatus : 4|4@1+ (1,0) [0|15] "" Vector__XXX

BO_ 2566876711 pVF1_39: 8 Vector__XXX
 SG_ pEngineOilPressureStatus : 4|2@1+ (1,0) [0|3] "" Vector__XXX
 SG_ pHydraulicOilPressureStatus : 2|2@1+ (1,0) [0|3] "" Vector__XXX
 SG_ pHydraulicOilTempStatus : 0|2@1+ (1,0) [0|3] "" Vector__XXX

BO_ 2633984551 pDriveSystemStatus_39: 8 Vector__XXX
 SG_ pHeatedGripEnable : 48|2@1+ (1,0) [0|3] "" Vector__XXX
 SG_ pSideStandStatus : 36|2@1+ (1,0) [0|3] "" Vector__XXX
 SG_ pTetherSwitchStatus : 46|2@1+ (1,0) [0|3] "" Vector__XXX
 SG_ pLowFuelIndicatorStatus : 10|2@1+ (1,0) [0|3] "" Vector__XXX
 SG_ pOperatorNotInOperatingStation : 38|2@1+ (1,0) [0|3] "" Vector__XXX
 SG_ pParkBrakeIndicatorStatus : 40|3@1+ (1,0) [0|7] "" Vector__XXX
 SG_ pADCRequested : 34|2@1+ (1,0) [0|3] "" Vector__XXX
 SG_ pAWDModeRequested : 32|2@1+ (1,0) [0|3] "" Vector__XXX
 SG_ pRWDModeRequested : 30|2@1+ (1,0) [0|3] "" Vector__XXX
 SG_ pTurfModeRequested : 28|2@1+ (1,0) [0|3] "" Vector__XXX
 SG_ pADCStatus : 0|2@1+ (1,0) [0|3] "" Vector__XXX
 SG_ pTreadleNeutralStatus : 2|2@1+ (1,0) [0|3] "" Vector__XXX
 SG_ pTreadleReverseStatus : 4|2@1+ (1,0) [0|3] "" Vector__XXX
 SG_ pSecurityLightStatus : 6|2@1+ (1,0) [0|3] "" Vector__XXX
 SG_ pHighBeamIndicatorStatus : 8|2@1+ (1,0) [0|3] "" Vector__XXX
 SG_ pHeatedGripsPercentage : 16|8@1+ (0.4,0) [0|100] "%" Vector__XXX
 SG_ pCruiseControlSetStatus : 24|2@1+ (1,0) [0|3] "" Vector__XXX
 SG_ pSeatBeltIndicatorStatus : 12|3@1+ (1,0) [0|7] "" Vector__XXX

BO_ 2432656679 pOperatorSwitchStatus_39: 8 Vector__XXX
 SG_ pOperatorButton29 : 58|2@1+ (1,0) [0|3] "" Vector__XXX
 SG_ pOperatorButton1 : 0|2@1+ (1,0) [0|3] "" Vector__XXX
 SG_ pOperatorButton2 : 2|2@1+ (1,0) [0|3] "" Vector__XXX
 SG_ pOperatorButton3 : 4|2@1+ (1,0) [0|3] "" Vector__XXX
 SG_ pOperatorButton4 : 6|2@1+ (1,0) [0|3] "" Vector__XXX
 SG_ pOperatorButton5 : 8|2@1+ (1,0) [0|3] "" Vector__XXX
 SG_ pOperatorButton6 : 10|2@1+ (1,0) [0|3] "" Vector__XXX
 SG_ pOperatorButton7 : 12|2@1+ (1,0) [0|3] "" Vector__XXX
 SG_ pOperatorButton8 : 14|2@1+ (1,0) [0|3] "" Vector__XXX
 SG_ pOperatorButton9 : 16|2@1+ (1,0) [0|3] "" Vector__XXX
 SG_ pOperatorButton10 : 18|2@1+ (1,0) [0|3] "" Vector__XXX
 SG_ pOperatorButton11 : 20|2@1+ (1,0) [0|3] "" Vector__XXX
 SG_ pOperatorButton12 : 22|2@1+ (1,0) [0|3] "" Vector__XXX
 SG_ pOperatorButton13 : 24|2@1+ (1,0) [0|3] "" Vector__XXX
 SG_ pOperatorButton14 : 26|2@1+ (1,0) [0|3] "" Vector__XXX
 SG_ pOperatorButton15 : 28|2@1+ (1,0) [0|3] "" Vector__XXX
 SG_ pOperatorButton16 : 30|2@1+ (1,0) [0|3] "" Vector__XXX
 SG_ pOperatorButton17 : 32|2@1+ (1,0) [0|3] "" Vector__XXX
 SG_ pOperatorButton18 : 34|2@1+ (1,0) [0|3] "" Vector__XXX
 SG_ pOperatorButton19 : 36|2@1+ (1,0) [0|3] "" Vector__XXX
 SG_ pOperatorButton20 : 38|2@1+ (1,0) [0|3] "" Vector__XXX
 SG_ pOperatorButton21 : 40|2@1+ (1,0) [0|3] "" Vector__XXX
 SG_ pOperatorButton22 : 42|2@1+ (1,0) [0|3] "" Vector__XXX
 SG_ pOperatorButton23 : 44|2@1+ (1,0) [0|3] "" Vector__XXX
 SG_ pOperatorButton24 : 46|2@1+ (1,0) [0|3] "" Vector__XXX
 SG_ pOperatorButton25 : 48|2@1+ (1,0) [0|3] "" Vector__XXX
 SG_ pOperatorButton26 : 50|2@1+ (1,0) [0|3] "" Vector__XXX
 SG_ pOperatorButton27 : 52|2@1+ (1,0) [0|3] "" Vector__XXX
 SG_ pOperatorButton28 : 54|2@1+ (1,0) [0|3] "" Vector__XXX
 SG_ pSideStandStatus : 56|2@1+ (1,0) [0|3] "" Vector__XXX

BO_ 2550791719 SRASI_39: 8 Vector__XXX
 SG_ StaticRollAngle : 0|8@1+ (1,-125) [-125|130] "Degrees" Vector__XXX
 SG_ StaticRollAngleStatus : 8|3@1+ (1,0) [0|7] "" Vector__XXX

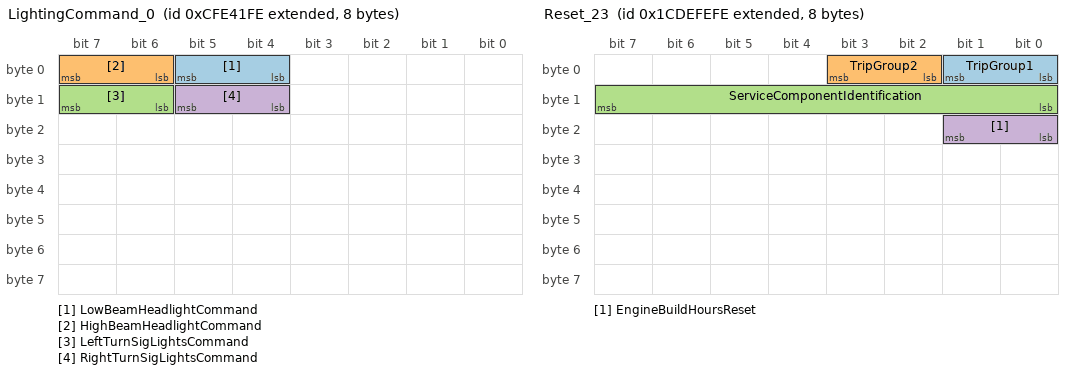
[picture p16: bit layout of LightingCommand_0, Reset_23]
BO_ 2365473278 LightingCommand_0: 8 Vector__XXX
 SG_ LowBeamHeadlightCommand : 4|2@1+ (1,0) [0|3] "" Vector__XXX
 SG_ HighBeamHeadlightCommand : 6|2@1+ (1,0) [0|3] "" Vector__XXX
 SG_ LeftTurnSigLightsCommand : 14|2@1+ (1,0) [0|3] "" Vector__XXX
 SG_ RightTurnSigLightsCommand : 12|2@1+ (1,0) [0|3] "" Vector__XXX

BO_ 2631859966 Reset_23: 8 Vector__XXX
 SG_ TripGroup1 : 0|2@1+ (1,0) [0|3] "" Vector__XXX
 SG_ TripGroup2 : 2|2@1+ (1,0) [0|3] "" Vector__XXX
 SG_ ServiceComponentIdentification : 8|8@1+ (1,0) [0|250] "" Vector__XXX
 SG_ EngineBuildHoursReset : 16|2@1+ (1,0) [0|3] "" Vector__XXX

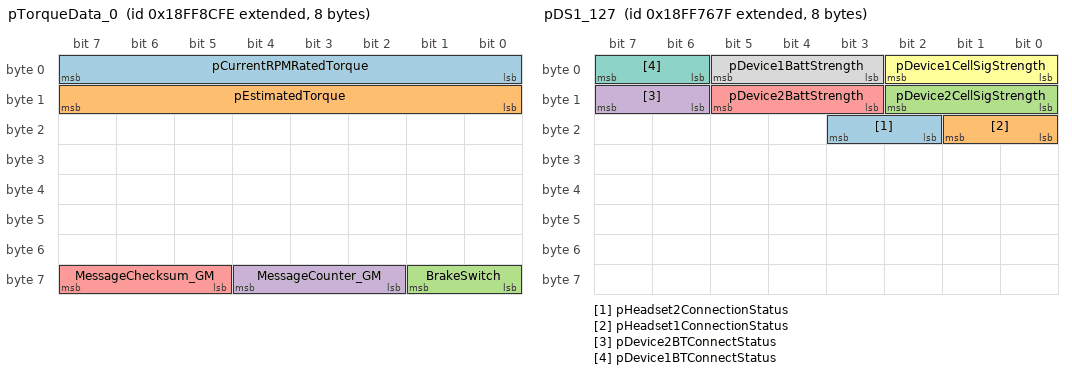
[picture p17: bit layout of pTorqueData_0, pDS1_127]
BO_ 2566884606 pTorqueData_0: 8 Vector__XXX
 SG_ pCurrentRPMRatedTorque : 0|8@1+ (0.03125,-1024) [-1024|1024] "Nm" Vector__XXX
 SG_ pEstimatedTorque : 8|8@1+ (0.03125,-1024) [-1024|1024] "Nm" Vector__XXX
 SG_ BrakeSwitch : 56|2@1+ (1,0) [0|3] "" Vector__XXX
 SG_ MessageCounter_GM : 58|3@1+ (1,0) [0|7] "" Vector__XXX
 SG_ MessageChecksum_GM : 61|3@1+ (1,0) [0|7] "" Vector__XXX

BO_ 2566878847 pDS1_127: 8 Vector__XXX
 SG_ pHeadset2ConnectionStatus : 18|2@1+ (1,0) [0|3] "" Vector__XXX
 SG_ pHeadset1ConnectionStatus : 16|2@1+ (1,0) [0|3] "" Vector__XXX
 SG_ pDevice2CellSigStrength : 8|3@1+ (1,0) [0|7] "" Vector__XXX
 SG_ pDevice2BTConnectStatus : 14|2@1+ (1,0) [0|3] "" Vector__XXX
 SG_ pDevice2BattStrength : 11|3@1+ (1,0) [0|7] "" Vector__XXX
 SG_ pDevice1CellSigStrength : 0|3@1+ (1,0) [0|7] "" Vector__XXX
 SG_ pDevice1BTConnectStatus : 6|2@1+ (1,0) [0|3] "" Vector__XXX
 SG_ pDevice1BattStrength : 3|3@1+ (1,0) [0|7] "" Vector__XXX

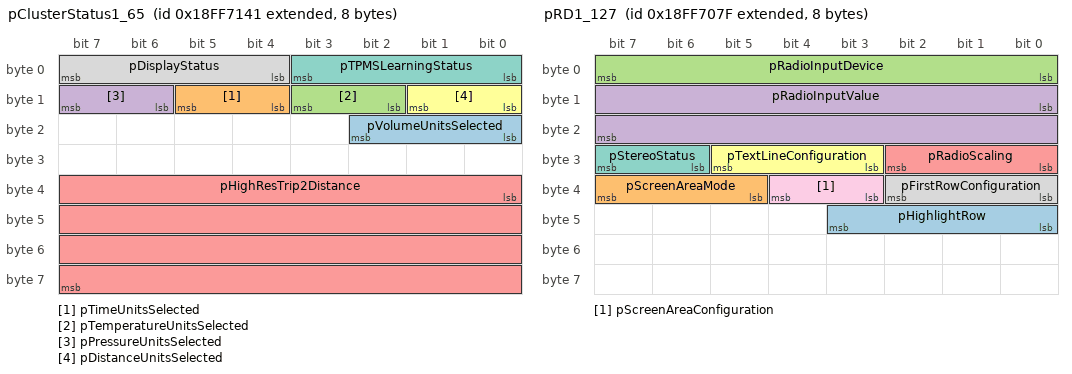
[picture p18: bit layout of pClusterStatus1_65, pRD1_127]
BO_ 2566877505 pClusterStatus1_65: 8 Vector__XXX
 SG_ pVolumeUnitsSelected : 16|3@1+ (1,0) [0|7] "" Vector__XXX
 SG_ pTimeUnitsSelected : 12|2@1+ (1,0) [0|3] "" Vector__XXX
 SG_ pTemperatureUnitsSelected : 10|2@1+ (1,0) [0|3] "" Vector__XXX
 SG_ pPressureUnitsSelected : 14|2@1+ (1,0) [0|3] "" Vector__XXX
 SG_ pHighResTrip2Distance : 32|32@1+ (0.005,0) [0|21055406] "km" Vector__XXX
 SG_ pDistanceUnitsSelected : 8|2@1+ (1,0) [0|3] "" Vector__XXX
 SG_ pTPMSLearningStatus : 0|4@1+ (1,0) [0|15] "" Vector__XXX
 SG_ pDisplayStatus : 4|4@1+ (1,0) [0|15] "" Vector__XXX

BO_ 2566877311 pRD1_127: 8 Vector__XXX
 SG_ pHighlightRow : 40|4@1+ (1,0) [0|15] "" Vector__XXX
 SG_ pScreenAreaMode : 37|3@1+ (1,0) [0|7] "" Vector__XXX
 SG_ pRadioInputDevice : 0|8@1+ (1,0) [0|65535] "" Vector__XXX
 SG_ pRadioInputValue : 8|16@1+ (1,0) [0|65535] "" Vector__XXX
 SG_ pRadioScaling : 24|3@1+ (1,0) [0|7] "" Vector__XXX
 SG_ pTextLineConfiguration : 27|3@1+ (1,0) [0|7] "" Vector__XXX
 SG_ pStereoStatus : 30|2@1+ (1,0) [0|3] "" Vector__XXX
 SG_ pFirstRowConfiguration : 32|3@1+ (1,0) [0|7] "" Vector__XXX
 SG_ pScreenAreaConfiguration : 35|2@1+ (1,0) [0|3] "" Vector__XXX

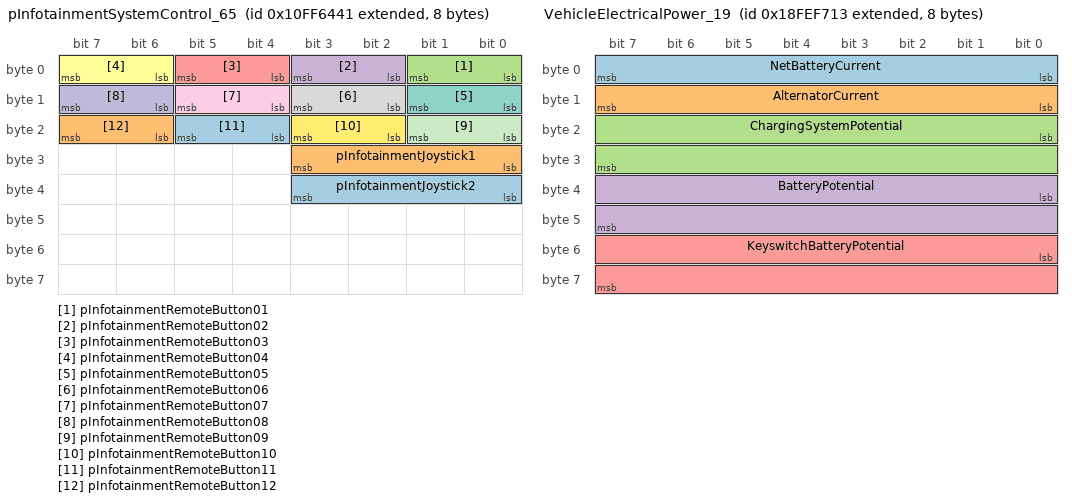
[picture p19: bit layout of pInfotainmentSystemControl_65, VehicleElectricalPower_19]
BO_ 2432656449 pInfotainmentSystemControl_65: 8 Vector__XXX
 SG_ pInfotainmentJoystick2 : 32|4@1+ (1,0) [0|15] "" Vector__XXX
 SG_ pInfotainmentJoystick1 : 24|4@1+ (1,0) [0|15] "" Vector__XXX
 SG_ pInfotainmentRemoteButton01 : 0|2@1+ (1,0) [0|3] "" Vector__XXX
 SG_ pInfotainmentRemoteButton02 : 2|2@1+ (1,0) [0|3] "" Vector__XXX
 SG_ pInfotainmentRemoteButton03 : 4|2@1+ (1,0) [0|3] "" Vector__XXX
 SG_ pInfotainmentRemoteButton04 : 6|2@1+ (1,0) [0|3] "" Vector__XXX
 SG_ pInfotainmentRemoteButton05 : 8|2@1+ (1,0) [0|3] "" Vector__XXX
 SG_ pInfotainmentRemoteButton06 : 10|2@1+ (1,0) [0|3] "" Vector__XXX
 SG_ pInfotainmentRemoteButton07 : 12|2@1+ (1,0) [0|3] "" Vector__XXX
 SG_ pInfotainmentRemoteButton08 : 14|2@1+ (1,0) [0|3] "" Vector__XXX
 SG_ pInfotainmentRemoteButton09 : 16|2@1+ (1,0) [0|3] "" Vector__XXX
 SG_ pInfotainmentRemoteButton10 : 18|2@1+ (1,0) [0|3] "" Vector__XXX
 SG_ pInfotainmentRemoteButton11 : 20|2@1+ (1,0) [0|3] "" Vector__XXX
 SG_ pInfotainmentRemoteButton12 : 22|2@1+ (1,0) [0|3] "" Vector__XXX

BO_ 2566874899 pElecPowerAssistedSteering_19: 8 STEERING_CONTROLLER
 SG_ pSensedInputSteeringTorque : 0|16@1+ (0.1,-3200) [-3200|3353.5] "Nm" Vector__XXX
 SG_ pSensedOutputSteeringTorque : 16|16@1+ (0.1,-3200) [-3200|3353.5] "Nm" Vector__XXX
 SG_ pGeneratedCurrentCommand : 32|8@1+ (1,-125) [-125|125] "A" Vector__XXX
 SG_ pVTemp : 40|8@1+ (1,-40) [-40|210] "C" Vector__XXX

BO_ 2566846227 VehicleElectricalPower_19: 8 STEERING_CONTROLLER
 SG_ NetBatteryCurrent : 0|8@1+ (1,-125) [-125|125] "A" Vector__XXX
 SG_ AlternatorCurrent : 8|8@1+ (1,0) [0|250] "A" Vector__XXX
 SG_ ChargingSystemPotential : 16|16@1+ (0.05,0) [0|3212.75] "V" Vector__XXX
 SG_ BatteryPotential : 32|16@1+ (0.05,0) [0|3212.75] "V" Vector__XXX
 SG_ KeyswitchBatteryPotential : 48|16@1+ (0.05,0) [0|3212.75] "V" Vector__XXX

CM_ BO_ 3221225472 "This is a message for not used signals, created by Vector CANdb++ DBC OLE DB Provider.";
CM_ SG_ 3221225472 WATT_pEPCU_2_Check_Sequence "Checksum ensures data is valid before use.";
CM_ SG_ 3221225472 WATT_pEPCU_2_Var_4 "This is the Propulsion Control Unit 2 variable 4";
CM_ SG_ 3221225472 WATT_pEPCU_2_Var_3 "This is the Propulsion Control Unit 2 variable 3";
CM_ SG_ 3221225472 WATT_pEPCU_2_Var_2 "This is the Propulsion Control Unit 2 variable 2";
CM_ SG_ 3221225472 WATT_pEPCU_2_Var_1 "This is the Propulsion Control Unit 2 variable 1";
CM_ SG_ 3221225472 WATT_pEPCU_2_cntrl "Bits dictating the commanded control mode of the second on-board device converting torque commands to current commands in an electric vehicle system.";
CM_ SG_ 2147483941 Torque_Actual_MCU "This is the actual motor torque sent from the MCU via CANOpen";
CM_ SG_ 2147483941 Max_Pwr_Lmt_Torque_MCU "The maximum torque available for accelerating in the positive direction from the MCU via CANOpen. In overspeed conditions the upper available torque may be negative.";
CM_ SG_ 2147483941 Capacitor_Voltage_MCU "Capacitor Voltage of the Electric Propulsion Control Unit from MCU via CANOpen 0x125";
CM_ SG_ 2147483940 Stator_Current_MCU "Stator Current of the Electric Propulsion Control Unit from MCU via CANOpen";
CM_ SG_ 2147483940 Input_Current_MCU "Input DC Current of the Electric Propulsion Control Unit from MCU via CANOpen";
CM_ BO_ 2566846298 "Vehicle Electrical Power Information";
CM_ SG_ 2566846298 NetBatteryCurrent "Net flow of electrical current into/out of the battery or batteries.";
CM_ SG_ 2566846298 AlternatorCurrent "Measure of electrical current flow from the alternator. Alternator Current (High Range/Resolution) parameter SPN 1795 has a higher range and resolution of the same parameter.";
CM_ SG_ 2566846298 ChargingSystemPotential "Electrical potential measured at the charging system output. The charging system may be any device charging the batteries. This includes alternators, generators, solid state charger,
and other charging devices.";
CM_ SG_ 2566846298 BatteryPotential "This parameter measures the first souce of battery potential as measured at the input of the ECM/actuator etc. coming from one or more batteries, irrespective of the distance between the component
and the battery.";
CM_ SG_ 2566846298 KeyswitchBatteryPotential "Battery potential measured at the input of the electronic control unit supplied through a keyswitch or similar switching device.";
CM_ SG_ 2566880525 MessageChecksum "The message checksum is used to verify the signal path from the transmitting device to the receiving device.";
CM_ BO_ 2566844762 "Cruise Control Status and Vehicle Speed Information";
CM_ SG_ 2566844762 TwoSpeedAxleSwitch "Switch signal which indicates the current axle range.";
CM_ SG_ 2566844762 ParkingBrakeSwitch "Switch signal which indicates when the parking brake is set. In general the switch actuated by the operator's park brake control,
whether a pedal, lever, or other control mechanism.";
CM_ SG_ 2566844762 Wheel_BasedVehicleSpeed "Speed of the vehicle as calculated from wheel or tailshaft speed.";
CM_ SG_ 2566844762 CruiseCtrlActive "Cruise control is switched on.  It is not ensured that the engine is controlled by cruise control, as in the case of a large driver's demand the engine is controlled by the driver while
cruise control is active.";
CM_ SG_ 2566844762 CruiseCtrlEnableSwitch "Switch signal which indicates that it is possible to manage the cruise control function";
CM_ SG_ 2566844762 BrakeSwitch "Switch signal which indicates that the driver operated brake foot pedal is being pressed";
CM_ SG_ 2566844762 ClutchSwitch "Switch signal which indicates that the clutch pedal is being pressed.  It is necessary for a safe drivetrain behavior that the clutch switch is set before the clutch is opened (cruise control function).";
CM_ SG_ 2566844762 CruiseCtrlSetSwitch "Switch signal of the cruise control activator which indicates that the activator is in the position 'set'.";
CM_ SG_ 2566844762 CruiseCtrlCoastSwitch "Switch signal of the cruise control activator which indicates that the activator is in the position 'coast'";
CM_ SG_ 2566844762 CruiseCtrlResumeSwitch "Switch signal of the cruise control activator which indicates that the activator is in the position 'resume'";
CM_ SG_ 2566844762 CruiseCtrlAccelerateSwitch "Switch signal of the cruise control activator which indicates that the activator is in the position 'accelerate'";
CM_ SG_ 2566844762 CruiseCtrlSetSpeed "Value of set (chosen) velocity of velocity control system.";
CM_ SG_ 2566844762 pOdometerDriveBit "Alternate state (A->B, B->A) each time the vehicle has moved a defined distance (currently 40m).";
CM_ SG_ 2566844762 CruiseCtrlPauseSw "Switch signal which indicates the positon of the Cruise Control Pause Switch used on Remote Cruise Control applications. The Cruise Control Pause Switch signal temporarily
disables the Cruise Control function.";
CM_ SG_ 2566844762 pCCMessageCounter "Rolling Counter (ensures updated message is used)";
CM_ SG_ 2566844762 pCCChecksum "XOR of bytes 0-6 (ensures data is valid before use)";
CM_ SG_ 2566844762 pCruiseEnableStatus "The Cruise Control System has been enabled by the operator.  (Amber Light)";
CM_ BO_ 2566844675 "Cruise Control Status and Vehicle Speed Information";
CM_ SG_ 2566844675 TwoSpeedAxleSwitch "Switch signal which indicates the current axle range.";
CM_ SG_ 2566844675 ParkingBrakeSwitch "Switch signal which indicates when the parking brake is set. In general the switch actuated by the operator's park brake control,
whether a pedal, lever, or other control mechanism.";
CM_ SG_ 2566844675 Wheel_BasedVehicleSpeed "Speed of the vehicle as calculated from wheel or tailshaft speed.";
CM_ SG_ 2566844675 CruiseCtrlActive "Cruise control is switched on.  It is not ensured that the engine is controlled by cruise control, as in the case of a large driver's demand the engine is controlled by the driver while
cruise control is active.";
CM_ SG_ 2566844675 CruiseCtrlEnableSwitch "Switch signal which indicates that it is possible to manage the cruise control function";
CM_ SG_ 2566844675 BrakeSwitch "Switch signal which indicates that the driver operated brake foot pedal is being pressed";
CM_ SG_ 2566844675 ClutchSwitch "Switch signal which indicates that the clutch pedal is being pressed.  It is necessary for a safe drivetrain behavior that the clutch switch is set before the clutch is opened (cruise control function).";
CM_ SG_ 2566844675 CruiseCtrlSetSwitch "Switch signal of the cruise control activator which indicates that the activator is in the position 'set'.";
CM_ SG_ 2566844675 CruiseCtrlCoastSwitch "Switch signal of the cruise control activator which indicates that the activator is in the position 'coast'";
CM_ SG_ 2566844675 CruiseCtrlResumeSwitch "Switch signal of the cruise control activator which indicates that the activator is in the position 'resume'";
CM_ SG_ 2566844675 CruiseCtrlAccelerateSwitch "Switch signal of the cruise control activator which indicates that the activator is in the position 'accelerate'";
CM_ SG_ 2566844675 CruiseCtrlSetSpeed "Value of set (chosen) velocity of velocity control system.";
CM_ SG_ 2566844675 pOdometerDriveBit "Alternate state (A->B, B->A) each time the vehicle has moved a defined distance (currently 40m).";
CM_ SG_ 2566844675 CruiseCtrlPauseSw "Switch signal which indicates the positon of the Cruise Control Pause Switch used on Remote Cruise Control applications. The Cruise Control Pause Switch signal temporarily
disables the Cruise Control function.";
CM_ SG_ 2566844675 pCCMessageCounter "Rolling Counter (ensures updated message is used)";
CM_ SG_ 2566844675 pCCChecksum "XOR of bytes 0-6 (ensures data is valid before use)";
CM_ SG_ 2566844675 pCruiseEnableStatus "The Cruise Control System has been enabled by the operator.  (Amber Light)";
CM_ BO_ 2565866755 "Electronic Transmission Controller 2";
CM_ SG_ 2565866755 TransmissionSelectedGear "The gear that the transmission will attempt to achieve during the current shift if a shift is in progress,
or the next shift if one is pending";
CM_ SG_ 2565866755 TransmissionActualGearRatio "Actual ratio of input shaft speed to output shaft speed";
CM_ SG_ 2565866755 TransmissionCurrentGear "The gear currently engaged in the transmission or the last gear engaged while the transmission is in
the process of shifting to the new or selected gear";
CM_ SG_ 2565866755 TransmissionRqstedRange "Range selected by the operator.";
CM_ SG_ 2565866755 TransmissionCurrentRange "Range currently being commanded by the transmission control system.";
CM_ BO_ 2365525594 "BMC Power Information";
CM_ SG_ 2365525594 WATT_pPack_Voltage "The voltage of the battery pack monitored by the Battery Management Controller (BMC).";
CM_ SG_ 2365525594 WATT_pPack_Current "The current of the battery pack monitored by the Battery Management Controller (BMC).";
CM_ SG_ 2365525594 WATT_pDischarge_Limit "The discharge limit of the battery pack monitored by the Battery Management Controller (BMC).";
CM_ SG_ 2365525594 WATT_pCharge_Limit "The Charge limit of the battery pack monitored by the Battery Management Controller (BMC).";
CM_ SG_ 2365525594 WATT_pBMC_Pwr_Msg_Check_Seq "Checksum ensures data is valid before use.";
CM_ BO_ 2231309146 "First or only on-board device converting torque commands to current commands in an electric vehicle system";
CM_ SG_ 2231309146 Check_Sequence "Checksum ensures data is valid before use. ";
CM_ SG_ 2231309146 Speed_Limit "This is the Propulsion Control Unit 1 variable 4";
CM_ SG_ 2231309146 Message_Counter "This is the Propulsion Control Unit 1 variable 3";
CM_ SG_ 2231309146 Counter_Torque_Limit "This is the Propulsion Control Unit 1 variable 2";
CM_ SG_ 2231309146 Torque_Demand "This is the Propulsion Control Unit 1 variable 1";
CM_ SG_ 2231309146 Control_Mode "Bits dictating the commanded control mode of the first or only on-board device converting torque commands to current commands in an electric vehicle system.";
CM_ BO_ 2432656894 "Indicates the status of multiple operator controlled switches.";
CM_ SG_ 2432656894 pOperatorButton29 "Drive Mode - 1()";
CM_ SG_ 2432656894 pOperatorButton1 "Instrument Cluster Control - 1";
CM_ SG_ 2432656894 pOperatorButton2 "Instrument Cluster Control  - 2";
CM_ SG_ 2432656894 pOperatorButton3 "Headlamp - 1 (Low)";
CM_ SG_ 2432656894 pOperatorButton4 "Headlamp - 2 (High)";
CM_ SG_ 2432656894 pOperatorButton5 "Headlamp - 3 (Driving)";
CM_ SG_ 2432656894 pOperatorButton6 "Turn - 1 (Left)";
CM_ SG_ 2432656894 pOperatorButton7 "Turn - 2 (Right)";
CM_ SG_ 2432656894 pOperatorButton8 "Turn - 3 (Cancel)";
CM_ SG_ 2432656894 pOperatorButton9 "Hazard";
CM_ SG_ 2432656894 pOperatorButton10 "Cruise - 1 (On)";
CM_ SG_ 2432656894 pOperatorButton11 "Cruise - 2 (Set)";
CM_ SG_ 2432656894 pOperatorButton12 "Cruise - 3 (Accel)";
CM_ SG_ 2432656894 pOperatorButton13 "Horn";
CM_ SG_ 2432656894 pOperatorButton14 "Start";
CM_ SG_ 2432656894 pOperatorButton15 "Warmer - 1";
CM_ SG_ 2432656894 pOperatorButton16 "Warmer - 2";
CM_ SG_ 2432656894 pOperatorButton17 "Warmer - 3";
CM_ SG_ 2432656894 pOperatorButton18 "Warmer - 4";
CM_ SG_ 2432656894 pOperatorButton19 "Windshield Wiper";
CM_ SG_ 2432656894 pOperatorButton20 "Engine On";
CM_ SG_ 2432656894 pOperatorButton21 "Reverse";
CM_ SG_ 2432656894 pOperatorButton22 "Suspension Adjust - 1 (Firm/Up)";
CM_ SG_ 2432656894 pOperatorButton23 "Suspension Adjust - 2 (Soft/Down)";
CM_ SG_ 2432656894 pOperatorButton24 "Throttle Safety Switch - 1";
CM_ SG_ 2432656894 pOperatorButton25 "Windshield - 1 (Up)";
CM_ SG_ 2432656894 pOperatorButton26 "Windshield - 2 (Down)";
CM_ SG_ 2432656894 pOperatorButton27 "Hand Brake Switch";
CM_ SG_ 2432656894 pOperatorButton28 "Clutch Switch";
CM_ SG_ 2432656894 pSideStandStatus "Status of the side stand switch of a motorcycle";
CM_ BO_ 2566878227 "Contains information which relates to a power steering unit with a sterring angle sensor";
CM_ SG_ 2566878227 pEPSShaftVelocity "The rotational velocity of the output shaft of the power steering unit";
CM_ SG_ 2566878227 pEPSShaftPosition "The absolute position of the output shaft of the power steering unit";
CM_ SG_ 2566878227 pEPSSASCalibrated "Indicates the calibration status of the EPS steering angle sensor";
CM_ SG_ 2566878227 pEPSOperationStatus "The operational stutas of the EPS unit";
CM_ SG_ 2566878227 pEPSOperationMode "The mode that the power steering unit is currently functioning in";
CM_ BO_ 2566877950 "pVehicle Temperature 1";
CM_ SG_ 2566877950 pLeftHandGripTemp "Temperature of the Left Hand grip";
CM_ SG_ 2566877950 pRightHandGripTemp "Temperature of the Right Hand grip";
CM_ BO_ 2566877694 "Instrument Cluster Information";
CM_ SG_ 2566877694 pVolumeUnitsSelected "Active display volume units beased on user selection or auto-configuration.";
CM_ SG_ 2566877694 pTimeUnitsSelected "Active display time units beased on user selection or auto-configuration.";
CM_ SG_ 2566877694 pTemperatureUnitsSelected "Active display temperature units beased on user selection or auto-configuration.";
CM_ SG_ 2566877694 pPressureUnitsSelected "Active display pressure units beased on user selection or auto-configuration.";
CM_ SG_ 2566877694 pHighResTrip2Distance "Secondary distance travled during all or part of a journey.";
CM_ SG_ 2566877694 pDistanceUnitsSelected "Active display distance units beased on user selection or auto-configuration.";
CM_ SG_ 2566877694 pTPMSLearningStatus "Status of the Tire Pressure Monitor System learning process.";
CM_ SG_ 2566877694 pDisplayStatus "Status of the radio display to the radio stating what the display is showing";
CM_ BO_ 2566876711 "Vehicle Fluid Information";
CM_ SG_ 2566876711 pEngineOilPressureStatus "Pressure Status of the Engine Oil";
CM_ SG_ 2566876711 pHydraulicOilPressureStatus "Pressure Status of the Hydraulic Oil Pressure";
CM_ SG_ 2566876711 pHydraulicOilTempStatus "Status of the hydraulic oil temperature";
CM_ BO_ 2633984551 "Status of Drive System Information";
CM_ SG_ 2633984551 pHeatedGripEnable "Indicates if the controller broadcasting this SPN is calibrated to support vehicle speed limit 3";
CM_ SG_ 2633984551 pSideStandStatus "Status of the side stand switch of a motorcycle";
CM_ SG_ 2633984551 pTetherSwitchStatus "Status of the Tether Switch";
CM_ SG_ 2633984551 pLowFuelIndicatorStatus "Broadcasting the status of the fuel level for user indication.";
CM_ SG_ 2633984551 pOperatorNotInOperatingStation "Status of Operator presence in a vehicle";
CM_ SG_ 2633984551 pParkBrakeIndicatorStatus "Broadcasting the status of the park brake for user indication";
CM_ SG_ 2633984551 pADCRequested "Broadcasting the status of the users request for ADC mode";
CM_ SG_ 2633984551 pAWDModeRequested "Broadcasting the status of the users request for AWD mode";
CM_ SG_ 2633984551 pRWDModeRequested "Broadcasting the status of the users request for RWD mode";
CM_ SG_ 2633984551 pTurfModeRequested "Broadcasting the status of the users request for TURF mode";
CM_ SG_ 2633984551 pADCStatus "Broadcasting the status of the ADC (active indicates the solenoid is powered)";
CM_ SG_ 2633984551 pTreadleNeutralStatus "Broadcasting the status of the switch indicating the treadle is/is not in the Neutral position";
CM_ SG_ 2633984551 pTreadleReverseStatus "Broadcasting the status of the switch indicating the treadle is/is not in the Reverse position";
CM_ SG_ 2633984551 pSecurityLightStatus "Broadcasting the status of the security system for user indication";
CM_ SG_ 2633984551 pHighBeamIndicatorStatus "Broadcasting the status of the high beam headlight for user indication";
CM_ SG_ 2633984551 pHeatedGripsPercentage "Heated Grips Percent On, 0% is Off and 100% is the maximum heat";
CM_ SG_ 2633984551 pCruiseControlSetStatus "Broadcasting the status of the Cruise Control Set Status for user indication";
CM_ SG_ 2633984551 pSeatBeltIndicatorStatus "Broadcasting the status of the seat belt for user indication";
CM_ BO_ 2432656679 "Indicates the status of multiple operator controlled switches.";
CM_ SG_ 2432656679 pOperatorButton29 "Drive Mode - 1()";
CM_ SG_ 2432656679 pOperatorButton1 "Instrument Cluster Control - 1";
CM_ SG_ 2432656679 pOperatorButton2 "Instrument Cluster Control  - 2";
CM_ SG_ 2432656679 pOperatorButton3 "Headlamp - 1 (Low)";
CM_ SG_ 2432656679 pOperatorButton4 "Headlamp - 2 (High)";
CM_ SG_ 2432656679 pOperatorButton5 "Headlamp - 3 (Driving)";
CM_ SG_ 2432656679 pOperatorButton6 "Turn - 1 (Left)";
CM_ SG_ 2432656679 pOperatorButton7 "Turn - 2 (Right)";
CM_ SG_ 2432656679 pOperatorButton8 "Turn - 3 (Cancel)";
CM_ SG_ 2432656679 pOperatorButton9 "Hazard";
CM_ SG_ 2432656679 pOperatorButton10 "Cruise - 1 (On)";
CM_ SG_ 2432656679 pOperatorButton11 "Cruise - 2 (Set)";
CM_ SG_ 2432656679 pOperatorButton12 "Cruise - 3 (Accel)";
CM_ SG_ 2432656679 pOperatorButton13 "Horn";
CM_ SG_ 2432656679 pOperatorButton14 "Start";
CM_ SG_ 2432656679 pOperatorButton15 "Warmer - 1";
CM_ SG_ 2432656679 pOperatorButton16 "Warmer - 2";
CM_ SG_ 2432656679 pOperatorButton17 "Warmer - 3";
CM_ SG_ 2432656679 pOperatorButton18 "Warmer - 4";
CM_ SG_ 2432656679 pOperatorButton19 "Windshield Wiper";
CM_ SG_ 2432656679 pOperatorButton20 "Engine On";
CM_ SG_ 2432656679 pOperatorButton21 "Reverse";
CM_ SG_ 2432656679 pOperatorButton22 "Suspension Adjust - 1 (Firm/Up)";
CM_ SG_ 2432656679 pOperatorButton23 "Suspension Adjust - 2 (Soft/Down)";
CM_ SG_ 2432656679 pOperatorButton24 "Throttle Safety Switch - 1";
CM_ SG_ 2432656679 pOperatorButton25 "Windshield - 1 (Up)";
CM_ SG_ 2432656679 pOperatorButton26 "Windshield - 2 (Down)";
CM_ SG_ 2432656679 pOperatorButton27 "Hand Brake Switch";
CM_ SG_ 2432656679 pOperatorButton28 "Clutch Switch";
CM_ SG_ 2432656679 pSideStandStatus "Status of the side stand switch of a motorcycle";
CM_ BO_ 2550791719 "Static Roll Angle Sensor Information";
CM_ SG_ 2550791719 StaticRollAngle "The measured static roll angle between the vehicle y-axis and the ground plane about the X-axis.";
CM_ SG_ 2550791719 StaticRollAngleStatus "Status of the transmitted roll angle data.";
CM_ BO_ 2365473278 "The lighting command message has been defined as a global message from the vehicle to all lighting controllers on the
tractor and attached implements.";
CM_ SG_ 2365473278 LowBeamHeadlightCommand "Command to activate or de-activate the tractor low beam head light lamps.";
CM_ SG_ 2365473278 HighBeamHeadlightCommand "Command to activate or de-activate the tractor high beam head light lamps.";
CM_ SG_ 2365473278 LeftTurnSigLightsCommand "Command to activate or de-activate left turn signal lights";
CM_ SG_ 2365473278 RightTurnSigLightsCommand "Command to activate or de-activate right turn signal lights on the tractor and all connected implements";
CM_ BO_ 2631859966 "Used to reset parameters of a controller when requested by the user or other controlling device.";
CM_ SG_ 2631859966 TripGroup1 "Command signal used to reset the PGNs and parameters as defined in Table SPN988_A.";
CM_ SG_ 2631859966 TripGroup2 "Command signal used to reset proprietary parameters associated with a trip but not defined in SAE J1939-71

Polaris defined paremeters to reset: PGN65266 Fuel Economy (Liquid), SPN 185 Average Fuel Economy";
CM_ SG_ 2631859966 ServiceComponentIdentification "Not approved for use at Polaris at this time.

(Identification of component needing service.)";
CM_ SG_ 2631859966 EngineBuildHoursReset "Not approved for use at Polaris at this time.

(Command signal used to reset the engine rebuild hours.)";
CM_ BO_ 2566884606 "Torque Data of Engine";
CM_ SG_ 2566884606 pCurrentRPMRatedTorque "Contains the rated torque for the current RPM (un-throttled and optimal spark).";
CM_ SG_ 2566884606 pEstimatedTorque "Estimated torque value based on current engine conditions.";
CM_ SG_ 2566884606 BrakeSwitch "Switch signal which indicates that the driver operated brake foot pedal is being pressed";
CM_ SG_ 2566884606 MessageChecksum_GM "The message checksum is used to verify the signal path from the transmitting device to the receiving device.";
CM_ BO_ 2566878847 "Device Status Information";
CM_ SG_ 2566878847 pHeadset2ConnectionStatus "Used to send the connection status of a connected Bluetooth headset. This typically will be the driver headset.";
CM_ SG_ 2566878847 pHeadset1ConnectionStatus "Used to send the connection status of a connected Bluetooth headset. This typically will be the driver headset.";
CM_ SG_ 2566878847 pDevice2CellSigStrength "Used to send the cell signal strength of a cell device to the infotainment display. This typically will be the driver device.";
CM_ SG_ 2566878847 pDevice2BTConnectStatus "Used to send the connection status of a connected Bluetooth device. This typically will be the driver device.";
CM_ SG_ 2566878847 pDevice2BattStrength "Used to send the battery strength of a connected device to the infotainment display. This typically will be the driver device.";
CM_ SG_ 2566878847 pDevice1CellSigStrength "Used to send the cell signal strength of a cell device to the infotainment display. This typically will be the driver device.";
CM_ SG_ 2566878847 pDevice1BTConnectStatus "Used to send the connection status of a connected Bluetooth device. This typically will be the driver device.";
CM_ SG_ 2566878847 pDevice1BattStrength "Used to send the battery strength of a connected device to the infotainment display. This typically will be the driver device.";
CM_ BO_ 2566877505 "Instrument Cluster Information";
CM_ SG_ 2566877505 pVolumeUnitsSelected "Active display volume units beased on user selection or auto-configuration.";
CM_ SG_ 2566877505 pTimeUnitsSelected "Active display time units beased on user selection or auto-configuration.";
CM_ SG_ 2566877505 pTemperatureUnitsSelected "Active display temperature units beased on user selection or auto-configuration.";
CM_ SG_ 2566877505 pPressureUnitsSelected "Active display pressure units beased on user selection or auto-configuration.";
CM_ SG_ 2566877505 pHighResTrip2Distance "Secondary distance travled during all or part of a journey.";
CM_ SG_ 2566877505 pDistanceUnitsSelected "Active display distance units beased on user selection or auto-configuration.";
CM_ SG_ 2566877505 pTPMSLearningStatus "Status of the Tire Pressure Monitor System learning process.";
CM_ SG_ 2566877505 pDisplayStatus "Status of the radio display to the radio stating what the display is showing";
CM_ BO_ 2566877311 "pRadio Display 1";
CM_ SG_ 2566877311 pHighlightRow "Number of row to highlight on the display.";
CM_ SG_ 2566877311 pScreenAreaMode "Broadcasting the type of information data being sent";
CM_ SG_ 2566877311 pRadioInputDevice "Broadcasting the source the radio is playing";
CM_ SG_ 2566877311 pRadioInputValue "Numerical value of channel or volume for display.";
CM_ SG_ 2566877311 pRadioScaling "Where to put the decimal for the pRadioScaling signal.";
CM_ SG_ 2566877311 pTextLineConfiguration "Number of lines of text being sent to the display";
CM_ SG_ 2566877311 pStereoStatus "Broadcasting the status of the radio reception";
CM_ SG_ 2566877311 pFirstRowConfiguration "Used to setup the radio display layout.";
CM_ SG_ 2566877311 pScreenAreaConfiguration "Used to setup the display screen size.";
CM_ BO_ 2432656449 "Infotaiment Button Status";
CM_ SG_ 2432656449 pInfotainmentJoystick2 "Switch signal which requests that all engine fueling and spark stop.";
CM_ SG_ 2432656449 pInfotainmentJoystick1 "Switch signal which requests that all engine fueling and spark stop.";
CM_ SG_ 2432656449 pInfotainmentRemoteButton01 "Volume Down";
CM_ SG_ 2432656449 pInfotainmentRemoteButton02 "Volume Up";
CM_ SG_ 2432656449 pInfotainmentRemoteButton03 "Tune Down";
CM_ SG_ 2432656449 pInfotainmentRemoteButton04 "Tune Up";
CM_ SG_ 2432656449 pInfotainmentRemoteButton05 "Source";
CM_ SG_ 2432656449 pInfotainmentRemoteButton06 "Mute";
CM_ SG_ 2432656449 pInfotainmentRemoteButton07 "ICOM";
CM_ SG_ 2432656449 pInfotainmentRemoteButton08 "COM";
CM_ SG_ 2432656449 pInfotainmentRemoteButton09 "Squelch (SQ) Down";
CM_ SG_ 2432656449 pInfotainmentRemoteButton10 "Squelch (SQ) Up";
CM_ SG_ 2432656449 pInfotainmentRemoteButton11 "Push To Talk (PTT)";
CM_ SG_ 2432656449 pInfotainmentRemoteButton12 "Preset";
CM_ BO_ 2566874899 "Signal group for Electric Power Assisted Steering";
CM_ SG_ 2566874899 pSensedInputSteeringTorque "?";
CM_ SG_ 2566874899 pSensedOutputSteeringTorque "?";
CM_ SG_ 2566874899 pGeneratedCurrentCommand "?";
CM_ SG_ 2566874899 pVTemp "Temperature of the PCB near the motor inverter.  Used to derate or turn off the inverter based on preset limits.";
CM_ BO_ 2566846227 "Vehicle Electrical Power Information";
CM_ SG_ 2566846227 NetBatteryCurrent "Net flow of electrical current into/out of the battery or batteries.";
CM_ SG_ 2566846227 AlternatorCurrent "Measure of electrical current flow from the alternator. Alternator Current (High Range/Resolution) parameter SPN 1795 has a higher range and resolution of the same parameter.";
CM_ SG_ 2566846227 ChargingSystemPotential "Electrical potential measured at the charging system output. The charging system may be any device charging the batteries. This includes alternators, generators, solid state charger,
and other charging devices.";
CM_ SG_ 2566846227 BatteryPotential "This parameter measures the first souce of battery potential as measured at the input of the ECM/actuator etc. coming from one or more batteries, irrespective of the distance between the component
and the battery.";
CM_ SG_ 2566846227 KeyswitchBatteryPotential "Battery potential measured at the input of the electronic control unit supplied through a keyswitch or similar switching device.";
BA_DEF_ BO_  "VFrameFormat" ENUM  "StandardCAN","ExtendedCAN","reserved","J1939PG";
BA_DEF_ SG_  "GenSigSendType" ENUM  "Cyclic","OnWrite","OnWriteWithRepetition","OnChange","OnChangeWithRepetition","IfActive","IfActiveWithRepetition","NoSigSendType";
BA_DEF_ SG_  "GenSigStartValue" INT 0 10000;
BA_DEF_ SG_  "GenSigEVName" STRING ;
BA_DEF_ SG_  "SPN" INT 0 524287;
BA_DEF_ SG_  "SigType" ENUM  "Default","Range","RangeSigned","ASCII","Discrete","Control","ReferencePGN","DTC","StringDelimiter","StringLength","StringLengthControl","MessageCounter","MessageChecksum";
BA_DEF_ SG_  "GenSigILSupport" ENUM  "No","Yes";
BA_DEF_ BO_  "GenMsgCycleTimeFast" INT 0 3600000;
BA_DEF_ BO_  "GenMsgILSupport" ENUM  "No","Yes";
BA_DEF_ BO_  "GenMsgStartDelayTime" INT 0 100000;
BA_DEF_ BO_  "GenMsgCycleTime" INT 0 3600000;
BA_DEF_ BO_  "GenMsgRequestable" INT 0 1;
BA_DEF_ BO_  "GenMsgSendType" ENUM  "cyclic","spontaneous","cyclicIfActive","spontaneousWithDelay","cyclicAndSpontaneous","cyclicAndSpontaneousWithDelay","spontaneousWithRepetition","cyclicIfActiveAndSpontaneousWD";
BA_DEF_ BU_  "NmStationAddress" INT 0 255;
BA_DEF_  "Specification" STRING ;
BA_DEF_  "ProtocolType" STRING ;
BA_DEF_  "BusType" STRING ;
BA_DEF_  "DBName" STRING ;
BA_DEF_DEF_  "VFrameFormat" "J1939PG";
BA_DEF_DEF_  "GenSigSendType" "NoSigSendType";
BA_DEF_DEF_  "GenSigStartValue" 0;
BA_DEF_DEF_  "GenSigEVName" "Env@Nodename_@Signame";
BA_DEF_DEF_  "SPN" 0;
BA_DEF_DEF_  "SigType" "Default";
BA_DEF_DEF_  "GenSigILSupport" "Yes";
BA_DEF_DEF_  "GenMsgCycleTimeFast" 0;
BA_DEF_DEF_  "GenMsgILSupport" "Yes";
BA_DEF_DEF_  "GenMsgStartDelayTime" 0;
BA_DEF_DEF_  "GenMsgCycleTime" 0;
BA_DEF_DEF_  "GenMsgRequestable" 1;
BA_DEF_DEF_  "GenMsgSendType" "cyclic";
BA_DEF_DEF_  "NmStationAddress" 254;
BA_DEF_DEF_  "Specification" "";
BA_DEF_DEF_  "ProtocolType" "";
BA_DEF_DEF_  "BusType" "CAN";
BA_DEF_DEF_  "DBName" "";
BA_ "ProtocolType" "J1939";
BA_ "Specification" "SAE J1939-71";
BA_ "DBName" "Polaris_j1939";
BA_ "NmStationAddress" BU_ PropulsionBatteryCharger 73;
BA_ "NmStationAddress" BU_ iBooster 13;
BA_ "NmStationAddress" BU_ TCM 3;
BA_ "NmStationAddress" BU_ HCU 90;
BA_ "NmStationAddress" BU_ STEERING_CONTROLLER 19;
BA_ "NmStationAddress" BU_ BMS 243;
BA_ "NmStationAddress" BU_ Traction_Motor_Controller 239;
BA_ "GenMsgCycleTime" BO_ 2566846298 1000;
BA_ "GenMsgCycleTimeFast" BO_ 2566885722 100;
BA_ "GenMsgCycleTime" BO_ 2566885722 100;
BA_ "GenMsgCycleTime" BO_ 2566841434 1000;
BA_ "GenMsgCycleTime" BO_ 2566841598 1000;
BA_ "GenMsgCycleTimeFast" BO_ 2566841598 1000;
BA_ "GenMsgCycleTime" BO_ 2348941146 50;
BA_ "GenMsgCycleTimeFast" BO_ 2348941059 50;
BA_ "GenMsgCycleTime" BO_ 2348941059 50;
BA_ "GenMsgCycleTime" BO_ 2566880525 10;
BA_ "GenMsgCycleTimeFast" BO_ 2566880525 10;
BA_ "GenMsgCycleTime" BO_ 2566844762 100;
BA_ "GenMsgCycleTime" BO_ 2566844675 100;
BA_ "GenMsgCycleTime" BO_ 2364539395 10;
BA_ "GenMsgCycleTimeFast" BO_ 2364539395 10;
BA_ "GenMsgCycleTime" BO_ 2565866755 100;
BA_ "GenMsgCycleTime" BO_ 2365525594 10;
BA_ "GenMsgCycleTime" BO_ 2231309146 10;
BA_ "GenMsgCycleTime" BO_ 2432656894 100;
BA_ "GenMsgCycleTimeFast" BO_ 2566878554 10;
BA_ "GenMsgCycleTime" BO_ 2566878554 10;
BA_ "GenMsgCycleTime" BO_ 2566878227 100;
BA_ "GenMsgCycleTime" BO_ 2566902782 100;
BA_ "GenMsgCycleTime" BO_ 2566877950 1000;
BA_ "GenMsgCycleTime" BO_ 2566877694 1000;
BA_ "GenMsgCycleTime" BO_ 2566876711 1000;
BA_ "GenMsgCycleTime" BO_ 2633984551 100;
BA_ "GenMsgCycleTime" BO_ 2432656679 100;
BA_ "GenMsgCycleTime" BO_ 2550791719 100;
BA_ "GenMsgCycleTime" BO_ 2365473278 100;
BA_ "GenMsgCycleTime" BO_ 2631859966 100;
BA_ "GenMsgCycleTime" BO_ 2566884606 20;
BA_ "GenMsgCycleTime" BO_ 2566878847 1000;
BA_ "GenMsgCycleTime" BO_ 2566877505 1000;
BA_ "GenMsgCycleTime" BO_ 2566877311 1000;
BA_ "GenMsgCycleTime" BO_ 2432656449 200;
BA_ "GenMsgCycleTime" BO_ 2566874899 100;
BA_ "GenMsgCycleTime" BO_ 2566846227 1000;
BA_ "SPN" SG_ 3221225472 WATT_pEPCU_2_Check_Sequence 524242;
BA_ "SPN" SG_ 3221225472 WATT_pEPCU_2_Var_4 524158;
BA_ "SPN" SG_ 3221225472 WATT_pEPCU_2_Var_3 524157;
BA_ "SPN" SG_ 3221225472 WATT_pEPCU_2_Var_2 524156;
BA_ "SPN" SG_ 3221225472 WATT_pEPCU_2_Var_1 524155;
BA_ "SPN" SG_ 3221225472 WATT_pEPCU_2_cntrl 524159;
BA_ "GenSigStartValue" SG_ 2365396297 BatteryCharger1Temperature 40;
BA_ "SPN" SG_ 2230359283 HVES1_Charge_Current_Limit 8083;
BA_ "GenSigStartValue" SG_ 2566722889 BatteryCharger1Temperature 40;
BA_ "SPN" SG_ 2566846298 NetBatteryCurrent 114;
BA_ "SigType" SG_ 2566846298 NetBatteryCurrent 1.7E-308;
BA_ "SPN" SG_ 2566846298 AlternatorCurrent 115;
BA_ "SigType" SG_ 2566846298 AlternatorCurrent 1.7E-308;
BA_ "SPN" SG_ 2566846298 ChargingSystemPotential 167;
BA_ "SigType" SG_ 2566846298 ChargingSystemPotential 1.7E-308;
BA_ "SPN" SG_ 2566846298 BatteryPotential 168;
BA_ "SigType" SG_ 2566846298 BatteryPotential 1.7E-308;
BA_ "SPN" SG_ 2566846298 KeyswitchBatteryPotential 158;
BA_ "SigType" SG_ 2566846298 KeyswitchBatteryPotential 1.7E-308;
BA_ "GenSigStartValue" SG_ 2147483695 Min_Cell_Temperature 40;
BA_ "GenSigStartValue" SG_ 2147483695 Max_Cell_Temperature 40;
BA_ "GenSigStartValue" SG_ 2147483679 Min_Cell_Temperature 40;
BA_ "GenSigStartValue" SG_ 2147483679 Max_Cell_Temperature 40;
BA_ "SPN" SG_ 2566880525 MessageChecksum 4207;
BA_ "SigType" SG_ 2566880525 MessageChecksum 1.7E-308;
BA_ "SPN" SG_ 2566844762 TwoSpeedAxleSwitch 69;
BA_ "SigType" SG_ 2566844762 TwoSpeedAxleSwitch 1.7E-308;
BA_ "SPN" SG_ 2566844762 ParkingBrakeSwitch 70;
BA_ "SigType" SG_ 2566844762 ParkingBrakeSwitch 1.7E-308;
BA_ "SPN" SG_ 2566844762 Wheel_BasedVehicleSpeed 84;
BA_ "SigType" SG_ 2566844762 Wheel_BasedVehicleSpeed 1.7E-308;
BA_ "SPN" SG_ 2566844762 CruiseCtrlActive 595;
BA_ "SigType" SG_ 2566844762 CruiseCtrlActive 1.7E-308;
BA_ "SPN" SG_ 2566844762 CruiseCtrlEnableSwitch 596;
BA_ "SigType" SG_ 2566844762 CruiseCtrlEnableSwitch 1.7E-308;
BA_ "SPN" SG_ 2566844762 BrakeSwitch 597;
BA_ "SigType" SG_ 2566844762 BrakeSwitch 1.7E-308;
BA_ "SPN" SG_ 2566844762 ClutchSwitch 598;
BA_ "SigType" SG_ 2566844762 ClutchSwitch 1.7E-308;
BA_ "SPN" SG_ 2566844762 CruiseCtrlSetSwitch 599;
BA_ "SigType" SG_ 2566844762 CruiseCtrlSetSwitch 1.7E-308;
BA_ "SPN" SG_ 2566844762 CruiseCtrlCoastSwitch 600;
BA_ "SigType" SG_ 2566844762 CruiseCtrlCoastSwitch 1.7E-308;
BA_ "SPN" SG_ 2566844762 CruiseCtrlResumeSwitch 601;
BA_ "SigType" SG_ 2566844762 CruiseCtrlResumeSwitch 1.7E-308;
BA_ "SPN" SG_ 2566844762 CruiseCtrlAccelerateSwitch 602;
BA_ "SigType" SG_ 2566844762 CruiseCtrlAccelerateSwitch 1.7E-308;
BA_ "SPN" SG_ 2566844762 CruiseCtrlSetSpeed 86;
BA_ "SigType" SG_ 2566844762 CruiseCtrlSetSpeed 1.7E-308;
BA_ "SPN" SG_ 2566844762 pOdometerDriveBit 523994;
BA_ "SigType" SG_ 2566844762 pOdometerDriveBit 1.7E-308;
BA_ "SPN" SG_ 2566844762 CruiseCtrlPauseSw 1633;
BA_ "SigType" SG_ 2566844762 CruiseCtrlPauseSw 1.7E-308;
BA_ "SPN" SG_ 2566844762 pCCMessageCounter 524080;
BA_ "SigType" SG_ 2566844762 pCCMessageCounter 1.7E-308;
BA_ "SPN" SG_ 2566844762 pCCChecksum 524079;
BA_ "SigType" SG_ 2566844762 pCCChecksum 1.7E-308;
BA_ "SPN" SG_ 2566844762 pCruiseEnableStatus 524108;
BA_ "SigType" SG_ 2566844762 pCruiseEnableStatus 1.7E-308;
BA_ "SPN" SG_ 2566844675 TwoSpeedAxleSwitch 69;
BA_ "SigType" SG_ 2566844675 TwoSpeedAxleSwitch 1.7E-308;
BA_ "SPN" SG_ 2566844675 ParkingBrakeSwitch 70;
BA_ "SigType" SG_ 2566844675 ParkingBrakeSwitch 1.7E-308;
BA_ "SPN" SG_ 2566844675 Wheel_BasedVehicleSpeed 84;
BA_ "SigType" SG_ 2566844675 Wheel_BasedVehicleSpeed 1.7E-308;
BA_ "SPN" SG_ 2566844675 CruiseCtrlActive 595;
BA_ "SigType" SG_ 2566844675 CruiseCtrlActive 1.7E-308;
BA_ "SPN" SG_ 2566844675 CruiseCtrlEnableSwitch 596;
BA_ "SigType" SG_ 2566844675 CruiseCtrlEnableSwitch 1.7E-308;
BA_ "SPN" SG_ 2566844675 BrakeSwitch 597;
BA_ "SigType" SG_ 2566844675 BrakeSwitch 1.7E-308;
BA_ "SPN" SG_ 2566844675 ClutchSwitch 598;
BA_ "SigType" SG_ 2566844675 ClutchSwitch 1.7E-308;
BA_ "SPN" SG_ 2566844675 CruiseCtrlSetSwitch 599;
BA_ "SigType" SG_ 2566844675 CruiseCtrlSetSwitch 1.7E-308;
BA_ "SPN" SG_ 2566844675 CruiseCtrlCoastSwitch 600;
BA_ "SigType" SG_ 2566844675 CruiseCtrlCoastSwitch 1.7E-308;
BA_ "SPN" SG_ 2566844675 CruiseCtrlResumeSwitch 601;
BA_ "SigType" SG_ 2566844675 CruiseCtrlResumeSwitch 1.7E-308;
BA_ "SPN" SG_ 2566844675 CruiseCtrlAccelerateSwitch 602;
BA_ "SigType" SG_ 2566844675 CruiseCtrlAccelerateSwitch 1.7E-308;
BA_ "SPN" SG_ 2566844675 CruiseCtrlSetSpeed 86;
BA_ "SigType" SG_ 2566844675 CruiseCtrlSetSpeed 1.7E-308;
BA_ "SPN" SG_ 2566844675 pOdometerDriveBit 523994;
BA_ "SigType" SG_ 2566844675 pOdometerDriveBit 1.7E-308;
BA_ "SPN" SG_ 2566844675 CruiseCtrlPauseSw 1633;
BA_ "SigType" SG_ 2566844675 CruiseCtrlPauseSw 1.7E-308;
BA_ "SPN" SG_ 2566844675 pCCMessageCounter 524080;
BA_ "SigType" SG_ 2566844675 pCCMessageCounter 1.7E-308;
BA_ "SPN" SG_ 2566844675 pCCChecksum 524079;
BA_ "SigType" SG_ 2566844675 pCCChecksum 1.7E-308;
BA_ "SPN" SG_ 2566844675 pCruiseEnableStatus 524108;
BA_ "SigType" SG_ 2566844675 pCruiseEnableStatus 1.7E-308;
BA_ "SPN" SG_ 2565866755 TransmissionSelectedGear 524;
BA_ "SigType" SG_ 2565866755 TransmissionSelectedGear 1.7E-308;
BA_ "SPN" SG_ 2565866755 TransmissionActualGearRatio 526;
BA_ "SigType" SG_ 2565866755 TransmissionActualGearRatio 1.7E-308;
BA_ "SPN" SG_ 2565866755 TransmissionCurrentGear 523;
BA_ "SigType" SG_ 2565866755 TransmissionCurrentGear 1.7E-308;
BA_ "SPN" SG_ 2565866755 TransmissionRqstedRange 162;
BA_ "SigType" SG_ 2565866755 TransmissionRqstedRange 1.7E-308;
BA_ "SPN" SG_ 2565866755 TransmissionCurrentRange 163;
BA_ "SigType" SG_ 2565866755 TransmissionCurrentRange 1.7E-308;
BA_ "SPN" SG_ 2365525594 WATT_pPack_Voltage 524217;
BA_ "SPN" SG_ 2365525594 WATT_pPack_Current 524216;
BA_ "SPN" SG_ 2365525594 WATT_pDischarge_Limit 524218;
BA_ "SPN" SG_ 2365525594 WATT_pCharge_Limit 524219;
BA_ "SPN" SG_ 2365525594 WATT_pBMC_Pwr_Msg_Check_Seq 524252;
BA_ "SPN" SG_ 2231309146 Check_Sequence 524241;
BA_ "SPN" SG_ 2231309146 Speed_Limit 524153;
BA_ "SPN" SG_ 2231309146 Message_Counter 524152;
BA_ "SPN" SG_ 2231309146 Counter_Torque_Limit 524151;
BA_ "SPN" SG_ 2231309146 Torque_Demand 524150;
BA_ "SPN" SG_ 2231309146 Control_Mode 524154;
BA_ "SPN" SG_ 2432656894 pOperatorButton29 524060;
BA_ "SPN" SG_ 2432656894 pOperatorButton1 524059;
BA_ "SigType" SG_ 2432656894 pOperatorButton1 1.7E-308;
BA_ "SPN" SG_ 2432656894 pOperatorButton2 524058;
BA_ "SigType" SG_ 2432656894 pOperatorButton2 1.7E-308;
BA_ "SPN" SG_ 2432656894 pOperatorButton3 524057;
BA_ "SigType" SG_ 2432656894 pOperatorButton3 1.7E-308;
BA_ "SPN" SG_ 2432656894 pOperatorButton4 524056;
BA_ "SigType" SG_ 2432656894 pOperatorButton4 1.7E-308;
BA_ "SPN" SG_ 2432656894 pOperatorButton5 524055;
BA_ "SigType" SG_ 2432656894 pOperatorButton5 1.7E-308;
BA_ "SPN" SG_ 2432656894 pOperatorButton6 524054;
BA_ "SigType" SG_ 2432656894 pOperatorButton6 1.7E-308;
BA_ "SPN" SG_ 2432656894 pOperatorButton7 524053;
BA_ "SigType" SG_ 2432656894 pOperatorButton7 1.7E-308;
BA_ "SPN" SG_ 2432656894 pOperatorButton8 524052;
BA_ "SigType" SG_ 2432656894 pOperatorButton8 1.7E-308;
BA_ "SPN" SG_ 2432656894 pOperatorButton9 524051;
BA_ "SigType" SG_ 2432656894 pOperatorButton9 1.7E-308;
BA_ "SPN" SG_ 2432656894 pOperatorButton10 524050;
BA_ "SigType" SG_ 2432656894 pOperatorButton10 1.7E-308;
BA_ "SPN" SG_ 2432656894 pOperatorButton11 524049;
BA_ "SigType" SG_ 2432656894 pOperatorButton11 1.7E-308;
BA_ "SPN" SG_ 2432656894 pOperatorButton12 524048;
BA_ "SigType" SG_ 2432656894 pOperatorButton12 1.7E-308;
BA_ "SPN" SG_ 2432656894 pOperatorButton13 524047;
BA_ "SigType" SG_ 2432656894 pOperatorButton13 1.7E-308;
BA_ "SPN" SG_ 2432656894 pOperatorButton14 524046;
BA_ "SigType" SG_ 2432656894 pOperatorButton14 1.7E-308;
BA_ "SPN" SG_ 2432656894 pOperatorButton15 524045;
BA_ "SigType" SG_ 2432656894 pOperatorButton15 1.7E-308;
BA_ "SPN" SG_ 2432656894 pOperatorButton16 524044;
BA_ "SigType" SG_ 2432656894 pOperatorButton16 1.7E-308;
BA_ "SPN" SG_ 2432656894 pOperatorButton17 524043;
BA_ "SigType" SG_ 2432656894 pOperatorButton17 1.7E-308;
BA_ "SPN" SG_ 2432656894 pOperatorButton18 524042;
BA_ "SigType" SG_ 2432656894 pOperatorButton18 1.7E-308;
BA_ "SPN" SG_ 2432656894 pOperatorButton19 524041;
BA_ "SigType" SG_ 2432656894 pOperatorButton19 1.7E-308;
BA_ "SPN" SG_ 2432656894 pOperatorButton20 524040;
BA_ "SigType" SG_ 2432656894 pOperatorButton20 1.7E-308;
BA_ "SPN" SG_ 2432656894 pOperatorButton21 524039;
BA_ "SigType" SG_ 2432656894 pOperatorButton21 1.7E-308;
BA_ "SPN" SG_ 2432656894 pOperatorButton22 524038;
BA_ "SigType" SG_ 2432656894 pOperatorButton22 1.7E-308;
BA_ "SPN" SG_ 2432656894 pOperatorButton23 524037;
BA_ "SigType" SG_ 2432656894 pOperatorButton23 1.7E-308;
BA_ "SPN" SG_ 2432656894 pOperatorButton24 524036;
BA_ "SigType" SG_ 2432656894 pOperatorButton24 1.7E-308;
BA_ "SPN" SG_ 2432656894 pOperatorButton25 524035;
BA_ "SigType" SG_ 2432656894 pOperatorButton25 1.7E-308;
BA_ "SPN" SG_ 2432656894 pOperatorButton26 524034;
BA_ "SigType" SG_ 2432656894 pOperatorButton26 1.7E-308;
BA_ "SPN" SG_ 2432656894 pOperatorButton27 520322;
BA_ "SigType" SG_ 2432656894 pOperatorButton27 1.7E-308;
BA_ "SPN" SG_ 2432656894 pOperatorButton28 524032;
BA_ "SigType" SG_ 2432656894 pOperatorButton28 1.7E-308;
BA_ "SPN" SG_ 2432656894 pSideStandStatus 524098;
BA_ "SigType" SG_ 2432656894 pSideStandStatus 1.7E-308;
BA_ "SPN" SG_ 2566878227 pEPSShaftVelocity 524115;
BA_ "SPN" SG_ 2566878227 pEPSShaftPosition 524114;
BA_ "SPN" SG_ 2566878227 pEPSSASCalibrated 524118;
BA_ "SPN" SG_ 2566878227 pEPSOperationStatus 524117;
BA_ "SPN" SG_ 2566878227 pEPSOperationMode 524116;
BA_ "SigType" SG_ 2566902782 DL_FiringMode 1.7E-308;
BA_ "SigType" SG_ 2566902782 DL_KnockMonitoring 1.7E-308;
BA_ "SigType" SG_ 2566902782 DL_KnockPresentInLastSec 1.7E-308;
BA_ "SigType" SG_ 2566902782 DL_FuelDetonationControlMode 1.7E-308;
BA_ "SigType" SG_ 2566902782 DL_OctaneRatingStatus 1.7E-308;
BA_ "SigType" SG_ 2566902782 DL_OctaneUpdate 1.7E-308;
BA_ "SigType" SG_ 2566902782 DL_SparkAdvance 1.7E-308;
BA_ "SigType" SG_ 2566902782 DL_CurrentMaxKnockRetardAllCyl 1.7E-308;
BA_ "SigType" SG_ 2566902782 DL_OctaneRating 1.7E-308;
BA_ "SigType" SG_ 2566902782 DL_CurrentCylWithMaxKnockRetard 1.7E-308;
BA_ "SigType" SG_ 2566902782 DL_CamAngle 1.7E-308;
BA_ "SPN" SG_ 2566877950 pLeftHandGripTemp 524109;
BA_ "SigType" SG_ 2566877950 pLeftHandGripTemp 1.7E-308;
BA_ "SPN" SG_ 2566877950 pRightHandGripTemp 524110;
BA_ "SigType" SG_ 2566877950 pRightHandGripTemp 1.7E-308;
BA_ "SPN" SG_ 2566877694 pVolumeUnitsSelected 524267;
BA_ "SPN" SG_ 2566877694 pTimeUnitsSelected 524268;
BA_ "SPN" SG_ 2566877694 pTemperatureUnitsSelected 524266;
BA_ "SPN" SG_ 2566877694 pPressureUnitsSelected 524269;
BA_ "SPN" SG_ 2566877694 pHighResTrip2Distance 524264;
BA_ "SPN" SG_ 2566877694 pDistanceUnitsSelected 524265;
BA_ "SPN" SG_ 2566877694 pTPMSLearningStatus 524104;
BA_ "SigType" SG_ 2566877694 pTPMSLearningStatus 1.7E-308;
BA_ "SPN" SG_ 2566877694 pDisplayStatus 524105;
BA_ "SigType" SG_ 2566877694 pDisplayStatus 1.7E-308;
BA_ "SPN" SG_ 2566876711 pEngineOilPressureStatus 524076;
BA_ "SigType" SG_ 2566876711 pEngineOilPressureStatus 1.7E-308;
BA_ "SPN" SG_ 2566876711 pHydraulicOilPressureStatus 524075;
BA_ "SigType" SG_ 2566876711 pHydraulicOilPressureStatus 1.7E-308;
BA_ "SPN" SG_ 2566876711 pHydraulicOilTempStatus 524074;
BA_ "SigType" SG_ 2566876711 pHydraulicOilTempStatus 1.7E-308;
BA_ "SPN" SG_ 2633984551 pHeatedGripEnable 520366;
BA_ "SPN" SG_ 2633984551 pSideStandStatus 524098;
BA_ "SigType" SG_ 2633984551 pSideStandStatus 1.7E-308;
BA_ "SPN" SG_ 2633984551 pTetherSwitchStatus 520600;
BA_ "SPN" SG_ 2633984551 pLowFuelIndicatorStatus 524087;
BA_ "SPN" SG_ 2633984551 pOperatorNotInOperatingStation 2832;
BA_ "SPN" SG_ 2633984551 pParkBrakeIndicatorStatus 524271;
BA_ "SPN" SG_ 2633984551 pADCRequested 524139;
BA_ "SPN" SG_ 2633984551 pAWDModeRequested 524138;
BA_ "SPN" SG_ 2633984551 pRWDModeRequested 524137;
BA_ "SPN" SG_ 2633984551 pTurfModeRequested 524136;
BA_ "SPN" SG_ 2633984551 pADCStatus 524013;
BA_ "SigType" SG_ 2633984551 pADCStatus 1.7E-308;
BA_ "SPN" SG_ 2633984551 pTreadleNeutralStatus 524017;
BA_ "SigType" SG_ 2633984551 pTreadleNeutralStatus 1.7E-308;
BA_ "SPN" SG_ 2633984551 pTreadleReverseStatus 524018;
BA_ "SigType" SG_ 2633984551 pTreadleReverseStatus 1.7E-308;
BA_ "SPN" SG_ 2633984551 pSecurityLightStatus 524019;
BA_ "SigType" SG_ 2633984551 pSecurityLightStatus 1.7E-308;
BA_ "SPN" SG_ 2633984551 pHighBeamIndicatorStatus 524084;
BA_ "SigType" SG_ 2633984551 pHighBeamIndicatorStatus 1.7E-308;
BA_ "SPN" SG_ 2633984551 pHeatedGripsPercentage 524096;
BA_ "SigType" SG_ 2633984551 pHeatedGripsPercentage 1.7E-308;
BA_ "SPN" SG_ 2633984551 pCruiseControlSetStatus 524097;
BA_ "SigType" SG_ 2633984551 pCruiseControlSetStatus 1.7E-308;
BA_ "SPN" SG_ 2633984551 pSeatBeltIndicatorStatus 524092;
BA_ "SigType" SG_ 2633984551 pSeatBeltIndicatorStatus 1.7E-308;
BA_ "SPN" SG_ 2432656679 pOperatorButton29 524060;
BA_ "SPN" SG_ 2432656679 pOperatorButton1 524059;
BA_ "SigType" SG_ 2432656679 pOperatorButton1 1.7E-308;
BA_ "SPN" SG_ 2432656679 pOperatorButton2 524058;
BA_ "SigType" SG_ 2432656679 pOperatorButton2 1.7E-308;
BA_ "SPN" SG_ 2432656679 pOperatorButton3 524057;
BA_ "SigType" SG_ 2432656679 pOperatorButton3 1.7E-308;
BA_ "SPN" SG_ 2432656679 pOperatorButton4 524056;
BA_ "SigType" SG_ 2432656679 pOperatorButton4 1.7E-308;
BA_ "SPN" SG_ 2432656679 pOperatorButton5 524055;
BA_ "SigType" SG_ 2432656679 pOperatorButton5 1.7E-308;
BA_ "SPN" SG_ 2432656679 pOperatorButton6 524054;
BA_ "SigType" SG_ 2432656679 pOperatorButton6 1.7E-308;
BA_ "SPN" SG_ 2432656679 pOperatorButton7 524053;
BA_ "SigType" SG_ 2432656679 pOperatorButton7 1.7E-308;
BA_ "SPN" SG_ 2432656679 pOperatorButton8 524052;
BA_ "SigType" SG_ 2432656679 pOperatorButton8 1.7E-308;
BA_ "SPN" SG_ 2432656679 pOperatorButton9 524051;
BA_ "SigType" SG_ 2432656679 pOperatorButton9 1.7E-308;
BA_ "SPN" SG_ 2432656679 pOperatorButton10 524050;
BA_ "SigType" SG_ 2432656679 pOperatorButton10 1.7E-308;
BA_ "SPN" SG_ 2432656679 pOperatorButton11 524049;
BA_ "SigType" SG_ 2432656679 pOperatorButton11 1.7E-308;
BA_ "SPN" SG_ 2432656679 pOperatorButton12 524048;
BA_ "SigType" SG_ 2432656679 pOperatorButton12 1.7E-308;
BA_ "SPN" SG_ 2432656679 pOperatorButton13 524047;
BA_ "SigType" SG_ 2432656679 pOperatorButton13 1.7E-308;
BA_ "SPN" SG_ 2432656679 pOperatorButton14 524046;
BA_ "SigType" SG_ 2432656679 pOperatorButton14 1.7E-308;
BA_ "SPN" SG_ 2432656679 pOperatorButton15 524045;
BA_ "SigType" SG_ 2432656679 pOperatorButton15 1.7E-308;
BA_ "SPN" SG_ 2432656679 pOperatorButton16 524044;
BA_ "SigType" SG_ 2432656679 pOperatorButton16 1.7E-308;
BA_ "SPN" SG_ 2432656679 pOperatorButton17 524043;
BA_ "SigType" SG_ 2432656679 pOperatorButton17 1.7E-308;
BA_ "SPN" SG_ 2432656679 pOperatorButton18 524042;
BA_ "SigType" SG_ 2432656679 pOperatorButton18 1.7E-308;
BA_ "SPN" SG_ 2432656679 pOperatorButton19 524041;
BA_ "SigType" SG_ 2432656679 pOperatorButton19 1.7E-308;
BA_ "SPN" SG_ 2432656679 pOperatorButton20 524040;
BA_ "SigType" SG_ 2432656679 pOperatorButton20 1.7E-308;
BA_ "SPN" SG_ 2432656679 pOperatorButton21 524039;
BA_ "SigType" SG_ 2432656679 pOperatorButton21 1.7E-308;
BA_ "SPN" SG_ 2432656679 pOperatorButton22 524038;
BA_ "SigType" SG_ 2432656679 pOperatorButton22 1.7E-308;
BA_ "SPN" SG_ 2432656679 pOperatorButton23 524037;
BA_ "SigType" SG_ 2432656679 pOperatorButton23 1.7E-308;
BA_ "SPN" SG_ 2432656679 pOperatorButton24 524036;
BA_ "SigType" SG_ 2432656679 pOperatorButton24 1.7E-308;
BA_ "SPN" SG_ 2432656679 pOperatorButton25 524035;
BA_ "SigType" SG_ 2432656679 pOperatorButton25 1.7E-308;
BA_ "SPN" SG_ 2432656679 pOperatorButton26 524034;
BA_ "SigType" SG_ 2432656679 pOperatorButton26 1.7E-308;
BA_ "SPN" SG_ 2432656679 pOperatorButton27 520322;
BA_ "SigType" SG_ 2432656679 pOperatorButton27 1.7E-308;
BA_ "SPN" SG_ 2432656679 pOperatorButton28 524032;
BA_ "SigType" SG_ 2432656679 pOperatorButton28 1.7E-308;
BA_ "SPN" SG_ 2432656679 pSideStandStatus 524098;
BA_ "SigType" SG_ 2432656679 pSideStandStatus 1.7E-308;
BA_ "SPN" SG_ 2550791719 StaticRollAngle 5582;
BA_ "SigType" SG_ 2550791719 StaticRollAngle 1.7E-308;
BA_ "SPN" SG_ 2550791719 StaticRollAngleStatus 5582;
BA_ "SigType" SG_ 2550791719 StaticRollAngleStatus 1.7E-308;
BA_ "SPN" SG_ 2365473278 LowBeamHeadlightCommand 2349;
BA_ "SPN" SG_ 2365473278 HighBeamHeadlightCommand 2347;
BA_ "SPN" SG_ 2365473278 LeftTurnSigLightsCommand 2367;
BA_ "SigType" SG_ 2365473278 LeftTurnSigLightsCommand 1.7E-308;
BA_ "SPN" SG_ 2365473278 RightTurnSigLightsCommand 2369;
BA_ "SigType" SG_ 2365473278 RightTurnSigLightsCommand 1.7E-308;
BA_ "SPN" SG_ 2631859966 TripGroup1 988;
BA_ "SigType" SG_ 2631859966 TripGroup1 1.7E-308;
BA_ "SPN" SG_ 2631859966 TripGroup2 989;
BA_ "SigType" SG_ 2631859966 TripGroup2 1.7E-308;
BA_ "SPN" SG_ 2631859966 ServiceComponentIdentification 1584;
BA_ "SigType" SG_ 2631859966 ServiceComponentIdentification 1.7E-308;
BA_ "SPN" SG_ 2631859966 EngineBuildHoursReset 1211;
BA_ "SigType" SG_ 2631859966 EngineBuildHoursReset 1.7E-308;
BA_ "SPN" SG_ 2566884606 pCurrentRPMRatedTorque 520245;
BA_ "SigType" SG_ 2566884606 pCurrentRPMRatedTorque 1.7E-308;
BA_ "SPN" SG_ 2566884606 pEstimatedTorque 520246;
BA_ "SigType" SG_ 2566884606 pEstimatedTorque 1.7E-308;
BA_ "SPN" SG_ 2566884606 BrakeSwitch 597;
BA_ "SigType" SG_ 2566884606 BrakeSwitch 1.7E-308;
BA_ "SPN" SG_ 2566884606 MessageCounter_GM 4206;
BA_ "SigType" SG_ 2566884606 MessageCounter_GM 1.7E-308;
BA_ "SPN" SG_ 2566884606 MessageChecksum_GM 4207;
BA_ "SigType" SG_ 2566884606 MessageChecksum_GM 1.7E-308;
BA_ "SPN" SG_ 2566878847 pHeadset2ConnectionStatus 524131;
BA_ "SPN" SG_ 2566878847 pHeadset1ConnectionStatus 524130;
BA_ "SPN" SG_ 2566878847 pDevice2CellSigStrength 524127;
BA_ "SPN" SG_ 2566878847 pDevice2BTConnectStatus 524129;
BA_ "SPN" SG_ 2566878847 pDevice2BattStrength 524128;
BA_ "SPN" SG_ 2566878847 pDevice1CellSigStrength 524124;
BA_ "SPN" SG_ 2566878847 pDevice1BTConnectStatus 524126;
BA_ "SPN" SG_ 2566878847 pDevice1BattStrength 524125;
BA_ "SPN" SG_ 2566877505 pVolumeUnitsSelected 524267;
BA_ "SPN" SG_ 2566877505 pTimeUnitsSelected 524268;
BA_ "SPN" SG_ 2566877505 pTemperatureUnitsSelected 524266;
BA_ "SPN" SG_ 2566877505 pPressureUnitsSelected 524269;
BA_ "SPN" SG_ 2566877505 pHighResTrip2Distance 524264;
BA_ "SPN" SG_ 2566877505 pDistanceUnitsSelected 524265;
BA_ "SPN" SG_ 2566877505 pTPMSLearningStatus 524104;
BA_ "SigType" SG_ 2566877505 pTPMSLearningStatus 1.7E-308;
BA_ "SPN" SG_ 2566877505 pDisplayStatus 524105;
BA_ "SigType" SG_ 2566877505 pDisplayStatus 1.7E-308;
BA_ "SPN" SG_ 2566877311 pHighlightRow 524119;
BA_ "SPN" SG_ 2566877311 pScreenAreaMode 524132;
BA_ "SPN" SG_ 2566877311 pRadioInputDevice 524099;
BA_ "SigType" SG_ 2566877311 pRadioInputDevice 1.7E-308;
BA_ "SPN" SG_ 2566877311 pRadioInputValue 524100;
BA_ "SigType" SG_ 2566877311 pRadioInputValue 1.7E-308;
BA_ "SPN" SG_ 2566877311 pRadioScaling 524101;
BA_ "SigType" SG_ 2566877311 pRadioScaling 1.7E-308;
BA_ "SPN" SG_ 2566877311 pTextLineConfiguration 524102;
BA_ "SigType" SG_ 2566877311 pTextLineConfiguration 1.7E-308;
BA_ "SPN" SG_ 2566877311 pStereoStatus 524103;
BA_ "SigType" SG_ 2566877311 pStereoStatus 1.7E-308;
BA_ "SPN" SG_ 2566877311 pFirstRowConfiguration 524106;
BA_ "SigType" SG_ 2566877311 pFirstRowConfiguration 1.7E-308;
BA_ "SPN" SG_ 2566877311 pScreenAreaConfiguration 524107;
BA_ "SigType" SG_ 2566877311 pScreenAreaConfiguration 1.7E-308;
BA_ "SPN" SG_ 2432656449 pInfotainmentJoystick2 520364;
BA_ "SPN" SG_ 2432656449 pInfotainmentJoystick1 520363;
BA_ "SPN" SG_ 2432656449 pInfotainmentRemoteButton01 524031;
BA_ "SigType" SG_ 2432656449 pInfotainmentRemoteButton01 1.7E-308;
BA_ "SPN" SG_ 2432656449 pInfotainmentRemoteButton02 524030;
BA_ "SigType" SG_ 2432656449 pInfotainmentRemoteButton02 1.7E-308;
BA_ "SPN" SG_ 2432656449 pInfotainmentRemoteButton03 524029;
BA_ "SigType" SG_ 2432656449 pInfotainmentRemoteButton03 1.7E-308;
BA_ "SPN" SG_ 2432656449 pInfotainmentRemoteButton04 524028;
BA_ "SigType" SG_ 2432656449 pInfotainmentRemoteButton04 1.7E-308;
BA_ "SPN" SG_ 2432656449 pInfotainmentRemoteButton05 524027;
BA_ "SigType" SG_ 2432656449 pInfotainmentRemoteButton05 1.7E-308;
BA_ "SPN" SG_ 2432656449 pInfotainmentRemoteButton06 524026;
BA_ "SigType" SG_ 2432656449 pInfotainmentRemoteButton06 1.7E-308;
BA_ "SPN" SG_ 2432656449 pInfotainmentRemoteButton07 524025;
BA_ "SigType" SG_ 2432656449 pInfotainmentRemoteButton07 1.7E-308;
BA_ "SPN" SG_ 2432656449 pInfotainmentRemoteButton08 524024;
BA_ "SigType" SG_ 2432656449 pInfotainmentRemoteButton08 1.7E-308;
BA_ "SPN" SG_ 2432656449 pInfotainmentRemoteButton09 524023;
BA_ "SigType" SG_ 2432656449 pInfotainmentRemoteButton09 1.7E-308;
BA_ "SPN" SG_ 2432656449 pInfotainmentRemoteButton10 524022;
BA_ "SigType" SG_ 2432656449 pInfotainmentRemoteButton10 1.7E-308;
BA_ "SPN" SG_ 2432656449 pInfotainmentRemoteButton11 524021;
BA_ "SigType" SG_ 2432656449 pInfotainmentRemoteButton11 1.7E-308;
BA_ "SPN" SG_ 2432656449 pInfotainmentRemoteButton12 524020;
BA_ "SigType" SG_ 2432656449 pInfotainmentRemoteButton12 1.7E-308;
BA_ "SPN" SG_ 2566874899 pSensedInputSteeringTorque 524002;
BA_ "SigType" SG_ 2566874899 pSensedInputSteeringTorque 1.7E-308;
BA_ "SPN" SG_ 2566874899 pSensedOutputSteeringTorque 524003;
BA_ "SigType" SG_ 2566874899 pSensedOutputSteeringTorque 1.7E-308;
BA_ "SPN" SG_ 2566874899 pGeneratedCurrentCommand 524004;
BA_ "SigType" SG_ 2566874899 pGeneratedCurrentCommand 1.7E-308;
BA_ "SPN" SG_ 2566874899 pVTemp 524005;
BA_ "SigType" SG_ 2566874899 pVTemp 1.7E-308;
BA_ "SPN" SG_ 2566846227 NetBatteryCurrent 114;
BA_ "SigType" SG_ 2566846227 NetBatteryCurrent 1.7E-308;
BA_ "SPN" SG_ 2566846227 AlternatorCurrent 115;
BA_ "SigType" SG_ 2566846227 AlternatorCurrent 1.7E-308;
BA_ "SPN" SG_ 2566846227 ChargingSystemPotential 167;
BA_ "SigType" SG_ 2566846227 ChargingSystemPotential 1.7E-308;
BA_ "SPN" SG_ 2566846227 BatteryPotential 168;
BA_ "SigType" SG_ 2566846227 BatteryPotential 1.7E-308;
BA_ "SPN" SG_ 2566846227 KeyswitchBatteryPotential 158;
BA_ "SigType" SG_ 2566846227 KeyswitchBatteryPotential 1.7E-308;
VAL_ 3221225472 BatteryOverVoltageAlarm 1 "Active" 0 "- - - - - -" ;
VAL_ 3221225472 WATT_pEPCU_2_cntrl 15 "No change in state" 14 "Reserved" 13 "Reserved" 12 "Reserved" 11 "Reserved for Active Discharge" 10 "Reserved for Control Vbat" 9 "Speed" 8 "Torque" 7 "Reserved" 6 "Reserved" 5 "Fault Reset" 4 "Reserved for End Active Short" 3 "Reserved for Active Short" 2 "Enable" 1 "Energize" 0 "Shutdown" ;
VAL_ 2365396297 BatteryCharger1State 3 "Disabled" 2 "Stand_by" 1 "Charging" 0 "Battery Disconnected" ;
VAL_ 2365396297 BatteryCharger1PowerLineState 3 "Not_Available" 2 "Error" 1 "Connected" 0 "Disconnected" ;
VAL_ 2316304912 Sendyne_Type 128 "Temperature_mC" 98 "Voltage_2_V" 97 "Voltage_1_V" 96 "Voltage_0_V" 65 "Coulomb_Count_High" 64 "Coulomb_Count_Low" 32 "Current_A" ;
VAL_ 2316304913 Sendyne_Type 128 "Temperature_mC" 98 "Voltage_2_V" 97 "Voltage_1_V" 96 "Voltage_0_V" 65 "Coulomb_Count_High" 64 "Coulomb_Count_Low" 32 "Current_A" ;
VAL_ 2566722889 BatteryCharger1State 3 "Disabled" 2 "Stand_by" 1 "Charging" 0 "Battery Disconnected" ;
VAL_ 2566722889 BatteryCharger1PowerLineState 3 "Not_Available" 2 "Error" 1 "Connected" 0 "Disconnected" ;
VAL_ 2147483691 BatteryCriticallyDischargedAlarm 1 "Active" 0 "- - - - - -" ;
VAL_ 2147483691 BatteryBelow20Percent 1 "Active" 0 "- - - - - -" ;
VAL_ 2147483691 BatteryOverTempWarning 1 "Active" 0 "- - - - - -" ;
VAL_ 2147483691 BatteryOverTempAlarm 1 "Active" 0 "- - - - - -" ;
VAL_ 2147483691 BatteryModuleLost 1 "Active" 0 "- - - - - -" ;
VAL_ 2147483691 BMS_Mode 2 "DRIVE" 1 "CHARGE" 0 "IDLE" ;
VAL_ 2147483675 BatteryCriticallyDischargedAlarm 1 "Active" 0 "- - - - - -" ;
VAL_ 2147483675 BatteryBelow20Percent 1 "Active" 0 "- - - - - -" ;
VAL_ 2147483675 BatteryOverTempWarning 1 "Active" 0 "- - - - - -" ;
VAL_ 2147483675 BatteryOverTempAlarm 1 "Active" 0 "- - - - - -" ;
VAL_ 2147483675 BatteryModuleLost 1 "Active" 0 "- - - - - -" ;
VAL_ 2147483675 BMS_Mode 2 "DRIVE" 1 "CHARGE" 0 "IDLE" ;
VAL_ 2566844762 TwoSpeedAxleSwitch 0 "LowSpeedRange" 1 "HighSpeedRange" 2 "Error" 3 "NotAvailable" ;
VAL_ 2566844762 ParkingBrakeSwitch 0 "NotSet" 1 "Set" 2 "Error" 3 "NotAvailable" ;
VAL_ 2566844762 CruiseCtrlActive 0 "SwitchedOff" 1 "SwitchedOn" 2 "Error" 3 "NotAvailable" ;
VAL_ 2566844762 CruiseCtrlEnableSwitch 0 "Disabled" 1 "Enabled" 2 "Error" 3 "NotAvailable" ;
VAL_ 2566844762 BrakeSwitch 0 "PedalReleased" 1 "PedalDepressed" 2 "Error" 3 "NotAvailable" ;
VAL_ 2566844762 ClutchSwitch 0 "PedalReleased" 1 "PedalDepressed" 2 "Error" 3 "NotAvailable" ;
VAL_ 2566844762 CruiseCtrlSetSwitch 0 "NotSet" 1 "Set" 2 "Error" 3 "NotAvailable" ;
VAL_ 2566844762 CruiseCtrlCoastSwitch 0 "NotCoast" 1 "Coast" 2 "Error" 3 "NotAvailable" ;
VAL_ 2566844762 CruiseCtrlResumeSwitch 0 "NotResume" 1 "Resume" 2 "Error" 3 "NotAvailable" ;
VAL_ 2566844762 CruiseCtrlAccelerateSwitch 0 "NotAccelerate" 1 "Accelerate" 2 "Error" 3 "NotAvailable" ;
VAL_ 2566844762 pOdometerDriveBit 0 "State A" 1 "State B" 2 "Error" 3 "Not Available/Initialize" ;
VAL_ 2566844762 CruiseCtrlPauseSw 0 "Off" 1 "On" 2 "Error" 3 "Take No Action" ;
VAL_ 2566844762 pCruiseEnableStatus 0 "Not enabled." 1 "Enabled but not activated." 2 "Reserved" 14 "Error Indicator" 15 "Not Available" ;
VAL_ 2566844675 TwoSpeedAxleSwitch 0 "LowSpeedRange" 1 "HighSpeedRange" 2 "Error" 3 "NotAvailable" ;
VAL_ 2566844675 ParkingBrakeSwitch 0 "NotSet" 1 "Set" 2 "Error" 3 "NotAvailable" ;
VAL_ 2566844675 CruiseCtrlActive 0 "SwitchedOff" 1 "SwitchedOn" 2 "Error" 3 "NotAvailable" ;
VAL_ 2566844675 CruiseCtrlEnableSwitch 0 "Disabled" 1 "Enabled" 2 "Error" 3 "NotAvailable" ;
VAL_ 2566844675 BrakeSwitch 0 "PedalReleased" 1 "PedalDepressed" 2 "Error" 3 "NotAvailable" ;
VAL_ 2566844675 ClutchSwitch 0 "PedalReleased" 1 "PedalDepressed" 2 "Error" 3 "NotAvailable" ;
VAL_ 2566844675 CruiseCtrlSetSwitch 0 "NotSet" 1 "Set" 2 "Error" 3 "NotAvailable" ;
VAL_ 2566844675 CruiseCtrlCoastSwitch 0 "NotCoast" 1 "Coast" 2 "Error" 3 "NotAvailable" ;
VAL_ 2566844675 CruiseCtrlResumeSwitch 0 "NotResume" 1 "Resume" 2 "Error" 3 "NotAvailable" ;
VAL_ 2566844675 CruiseCtrlAccelerateSwitch 0 "NotAccelerate" 1 "Accelerate" 2 "Error" 3 "NotAvailable" ;
VAL_ 2566844675 pOdometerDriveBit 0 "State A" 1 "State B" 2 "Error" 3 "Not Available/Initialize" ;
VAL_ 2566844675 CruiseCtrlPauseSw 0 "Off" 1 "On" 2 "Error" 3 "Take No Action" ;
VAL_ 2566844675 pCruiseEnableStatus 0 "Not enabled." 1 "Enabled but not activated." 2 "Reserved" 14 "Error Indicator" 15 "Not Available" ;
VAL_ 2231309146 Control_Mode 15 "No change in state" 14 "Reserved" 13 "Reserved" 12 "Reserved" 11 "Reserved for Active Discharge" 10 "Reserved for Control Vbat" 9 "Speed" 8 "Torque" 7 "Reserved" 6 "Reserved" 5 "Fault Reset" 4 "Reserved for End Active Short" 3 "Reserved for Active Short" 2 "Enable" 1 "Energize" 0 "Shutdown" ;
VAL_ 2432656894 pOperatorButton29 3 "Not Available" 2 "Error" 1 "Button Pressed" 0 "Button Not Pressed" ;
VAL_ 2432656894 pOperatorButton1 0 "Not Pressed" 1 "Pressed" 2 "Error" 3 "Not Available" ;
VAL_ 2432656894 pOperatorButton2 0 "Active" 1 "Inactive" 2 "Error" 3 "Not Available" ;
VAL_ 2432656894 pOperatorButton3 0 "Not Pressed" 1 "Pressed" 2 "Error" 3 "Not Available" ;
VAL_ 2432656894 pOperatorButton4 0 "Not Pressed" 1 "Pressed" 2 "Error" 3 "Not Available" ;
VAL_ 2432656894 pOperatorButton5 0 "Not Pressed" 1 "Pressed" 2 "Error" 3 "Not Available" ;
VAL_ 2432656894 pOperatorButton6 0 "Not Pressed" 1 "Pressed" 2 "Error" 3 "Not Available" ;
VAL_ 2432656894 pOperatorButton7 0 "Not Pressed" 1 "Pressed" 2 "Error" 3 "Not Available" ;
VAL_ 2432656894 pOperatorButton8 0 "Not Pressed" 1 "Pressed" 2 "Error" 3 "Not Available" ;
VAL_ 2432656894 pOperatorButton9 0 "Not Pressed" 1 "Pressed" 2 "Error" 3 "Not Available" ;
VAL_ 2432656894 pOperatorButton10 0 "Not Pressed" 1 "Pressed" 2 "Error" 3 "Not Available" ;
VAL_ 2432656894 pOperatorButton11 0 "Not Pressed" 1 "Pressed" 2 "Error" 3 "Not Available" ;
VAL_ 2432656894 pOperatorButton12 0 "Not Pressed" 1 "Pressed" 2 "Error" 3 "Not Available" ;
VAL_ 2432656894 pOperatorButton13 0 "Not Pressed" 1 "Pressed" 2 "Error" 3 "Not Available" ;
VAL_ 2432656894 pOperatorButton14 0 "Not Pressed" 1 "Pressed" 2 "Error" 3 "Not Available" ;
VAL_ 2432656894 pOperatorButton15 0 "Not Pressed" 1 "Pressed" 2 "Error" 3 "Not Available" ;
VAL_ 2432656894 pOperatorButton16 0 "Not Pressed" 1 "Pressed" 2 "Error" 3 "Not Available" ;
VAL_ 2432656894 pOperatorButton17 0 "Not Pressed" 1 "Pressed" 2 "Error" 3 "Not Available" ;
VAL_ 2432656894 pOperatorButton18 0 "Not Pressed" 1 "Pressed" 2 "Error" 3 "Not Available" ;
VAL_ 2432656894 pOperatorButton19 0 "Not Pressed" 1 "Pressed" 2 "Error" 3 "Not Available" ;
VAL_ 2432656894 pOperatorButton20 0 "Not Pressed" 1 "Pressed" 2 "Error" 3 "Not Available" ;
VAL_ 2432656894 pOperatorButton21 0 "Not Pressed" 1 "Pressed" 2 "Error" 3 "Not Available" ;
VAL_ 2432656894 pOperatorButton22 0 "Not Pressed" 1 "Pressed" 2 "Error" 3 "Not Available" ;
VAL_ 2432656894 pOperatorButton23 0 "Not Pressed" 1 "Pressed" 2 "Error" 3 "Not Available" ;
VAL_ 2432656894 pOperatorButton24 0 "Not Pressed" 1 "Pressed" 2 "Error" 3 "Not Available" ;
VAL_ 2432656894 pOperatorButton25 0 "Not Pressed" 1 "Pressed" 2 "Error" 3 "Not Available" ;
VAL_ 2432656894 pOperatorButton26 0 "Not Pressed" 1 "Pressed" 2 "Error" 3 "Not Available" ;
VAL_ 2432656894 pOperatorButton27 0 "Not Pressed" 1 "Pressed" 2 "Error" 3 "Not Available" ;
VAL_ 2432656894 pOperatorButton28 0 "Not Pressed" 1 "Pressed" 2 "Error" 3 "Not Available" ;
VAL_ 2432656894 pSideStandStatus 3 "Not Available" 2 "Error Indicator" 1 "Side Stand Up" 0 "Side Stand Down" ;
VAL_ 2566878227 pEPSSASCalibrated 3 "Not available" 2 "Reserved" 1 "SAS calibrated" 0 "SAS not calibrated" ;
VAL_ 2566878227 pEPSOperationStatus 7 "Not Available" 6 "Reserved" 5 "Error (non dunctional with DM1)" 4 "Not Used" 3 "Not Used" 2 "Limp Home Mode" 1 "Backup Mode" 0 "Fully Functional" ;
VAL_ 2566878227 pEPSOperationMode 16 "Set Position" 5 "Position w/Speed" 4 "Position" 3 "Speed" 2 "Torque Assist" 0 "Off" ;
VAL_ 2566902782 DL_FiringMode 0 "Individual" 1 "Paired" ;
VAL_ 2566902782 DL_KnockMonitoring 0 "Inactive" 1 "Active" ;
VAL_ 2566902782 DL_KnockPresentInLastSec 0 "False" 1 "True" ;
VAL_ 2566902782 DL_FuelDetonationControlMode 0 "Inactive" 1 "Active" ;
VAL_ 2566902782 DL_OctaneRatingStatus 0 "Disabled" 1 "Enabled" ;
VAL_ 2566902782 DL_OctaneUpdate 0 "Not in Progress" 1 "In" ;
VAL_ 2566877694 pVolumeUnitsSelected 7 "Not Available" 6 "Error" 5 "Reserved" 4 "Reserved" 3 "Reserved" 2 "Imperial Gallons" 1 "Liters" 0 "Gallons" ;
VAL_ 2566877694 pTimeUnitsSelected 3 "Not Available" 2 "Error" 1 "24 Hour" 0 "12 Hour" ;
VAL_ 2566877694 pTemperatureUnitsSelected 3 "Not Avaialable" 2 "Error" 1 "Celsius" 0 "Farenheit" ;
VAL_ 2566877694 pPressureUnitsSelected 3 "Not Available" 2 "Error" 1 "Kilopascal (kPa)" 0 "Pounds Per Square Inch (PSI)" ;
VAL_ 2566877694 pDistanceUnitsSelected 3 "Not Available" 2 "Error" 1 "Kilometers" 0 "Miles" ;
VAL_ 2566877694 pTPMSLearningStatus 0 "Not Started" 1 "Request to start" 2 "Learning Left Front" 3 "Learning Right Front" 4 "Learning Left Rear" 5 "Learning Right Rear" 6 "Learning successfully completed" 13 "Request to end learning" 14 "Error - Failed Learning" 15 "Not Available" ;
VAL_ 2566877694 pDisplayStatus 0 "Info cant overide to full screen" 1 "User requested full screen" 2 "Info can overide to full screen" 14 "Info data is not shown" 15 "Not Available" ;
VAL_ 2566876711 pEngineOilPressureStatus 0 "Not OK; Pressure is too low" 1 "OK; Pressure is above minimum" 2 "Error" 3 "Not Available" ;
VAL_ 2566876711 pHydraulicOilPressureStatus 0 "Not OK; Pressure too low" 1 "OK; Pressure above minimum" 2 "Error" 3 "Not Available" ;
VAL_ 2566876711 pHydraulicOilTempStatus 0 "Not OK; Temp too high" 1 "OK; Temp is below max" 2 "Error" 3 "Not Available" ;
VAL_ 2633984551 pHeatedGripEnable 3 "Description for the value '3'" 2 "Error Indicator" 1 "Enabled (Installed)" 0 "Disabled (Not installed)" ;
VAL_ 2633984551 pSideStandStatus 3 "Not Available" 2 "Error Indicator" 1 "Side Stand Up" 0 "Side Stand Down" ;
VAL_ 2633984551 pTetherSwitchStatus 3 "Not Available" 2 "Error" 1 "Tether SW Open (disconnected)" 0 "Tether SW Closed (connected)" ;
VAL_ 2633984551 pLowFuelIndicatorStatus 3 "Not Available" 2 "Error" 1 "Low Fuel Indicator On" 0 "Low Fuel Indicator Off" ;
VAL_ 2633984551 pOperatorNotInOperatingStation 3 "Description for the value '3'" 2 "Error" 1 "Operator Not In OperatorStation" 0 "Operator In OperatorStation" ;
VAL_ 2633984551 pParkBrakeIndicatorStatus 7 "Not Available" 6 "Error Indicator" 5 "Available for future use" 4 "Available for future use" 3 "Park Brake Indicator 2 Hz flash" 2 "Park Brake Indicator 1 Hz flash" 1 "Park Brake Indicator On (Solid)" 0 "Park Brake Indicator Off" ;
VAL_ 2633984551 pADCRequested 3 "Not Available" 2 "Error" 1 "ADC Mode Requested" 0 "ADC Mode not Requested" ;
VAL_ 2633984551 pAWDModeRequested 3 "Not Available" 2 "Error" 1 "AWD Mode Requested" 0 "AWD Mode not Requested" ;
VAL_ 2633984551 pRWDModeRequested 3 "Not Available" 2 "Error" 1 "RWD Mode Requested" 0 "RWD Mode not Requested" ;
VAL_ 2633984551 pTurfModeRequested 3 "Not Available" 2 "Error" 1 "Turf Mode Requested" 0 "Turf Mode not Requested" ;
VAL_ 2633984551 pADCStatus 0 "ADC Actuator Not Engaged" 1 "ADC Actuator Engaged" 2 "Error" 3 "Not available" ;
VAL_ 2633984551 pTreadleNeutralStatus 0 "Treadle Neutral Not Engaged" 1 "Treadle Neutral Engaged" 2 "Error" 3 "Not Available" ;
VAL_ 2633984551 pTreadleReverseStatus 0 "Treadle Reverse Not Engaged" 1 "Treadle Reverse Engaged" 2 "Error" 3 "Not Available" ;
VAL_ 2633984551 pSecurityLightStatus 0 "Off" 1 "On (Solid)" 2 "Error (Flashing)" 3 "Not Available" ;
VAL_ 2633984551 pHighBeamIndicatorStatus 0 "Indicator Off" 1 "Indicator On" 2 "Error (Indicator Flashing)" 3 "Not Available" ;
VAL_ 2633984551 pCruiseControlSetStatus 0 "Cruise Not Set" 1 "Cruise Set" 2 "Error (Lamp Flashing)" 3 "Not Available" ;
VAL_ 2633984551 pSeatBeltIndicatorStatus 0 "Seat_Belt_Indicator_Off" 1 "Seat_Belt_Indicator_On_Solid" 2 "Seat_Belt_Indicator_1Hz" 3 "Seat_Belt_Indicator_2Hz" 4 "Future1" 5 "Future2" 6 "Error" 7 "Not_Available" ;
VAL_ 2432656679 pOperatorButton29 3 "Not Available" 2 "Error" 1 "Button Pressed" 0 "Button Not Pressed" ;
VAL_ 2432656679 pOperatorButton1 0 "Not Pressed" 1 "Pressed" 2 "Error" 3 "Not Available" ;
VAL_ 2432656679 pOperatorButton2 0 "Active" 1 "Inactive" 2 "Error" 3 "Not Available" ;
VAL_ 2432656679 pOperatorButton3 0 "Not Pressed" 1 "Pressed" 2 "Error" 3 "Not Available" ;
VAL_ 2432656679 pOperatorButton4 0 "Not Pressed" 1 "Pressed" 2 "Error" 3 "Not Available" ;
VAL_ 2432656679 pOperatorButton5 0 "Not Pressed" 1 "Pressed" 2 "Error" 3 "Not Available" ;
VAL_ 2432656679 pOperatorButton6 0 "Not Pressed" 1 "Pressed" 2 "Error" 3 "Not Available" ;
VAL_ 2432656679 pOperatorButton7 0 "Not Pressed" 1 "Pressed" 2 "Error" 3 "Not Available" ;
VAL_ 2432656679 pOperatorButton8 0 "Not Pressed" 1 "Pressed" 2 "Error" 3 "Not Available" ;
VAL_ 2432656679 pOperatorButton9 0 "Not Pressed" 1 "Pressed" 2 "Error" 3 "Not Available" ;
VAL_ 2432656679 pOperatorButton10 0 "Not Pressed" 1 "Pressed" 2 "Error" 3 "Not Available" ;
VAL_ 2432656679 pOperatorButton11 0 "Not Pressed" 1 "Pressed" 2 "Error" 3 "Not Available" ;
VAL_ 2432656679 pOperatorButton12 0 "Not Pressed" 1 "Pressed" 2 "Error" 3 "Not Available" ;
VAL_ 2432656679 pOperatorButton13 0 "Not Pressed" 1 "Pressed" 2 "Error" 3 "Not Available" ;
VAL_ 2432656679 pOperatorButton14 0 "Not Pressed" 1 "Pressed" 2 "Error" 3 "Not Available" ;
VAL_ 2432656679 pOperatorButton15 0 "Not Pressed" 1 "Pressed" 2 "Error" 3 "Not Available" ;
VAL_ 2432656679 pOperatorButton16 0 "Not Pressed" 1 "Pressed" 2 "Error" 3 "Not Available" ;
VAL_ 2432656679 pOperatorButton17 0 "Not Pressed" 1 "Pressed" 2 "Error" 3 "Not Available" ;
VAL_ 2432656679 pOperatorButton18 0 "Not Pressed" 1 "Pressed" 2 "Error" 3 "Not Available" ;
VAL_ 2432656679 pOperatorButton19 0 "Not Pressed" 1 "Pressed" 2 "Error" 3 "Not Available" ;
VAL_ 2432656679 pOperatorButton20 0 "Not Pressed" 1 "Pressed" 2 "Error" 3 "Not Available" ;
VAL_ 2432656679 pOperatorButton21 0 "Not Pressed" 1 "Pressed" 2 "Error" 3 "Not Available" ;
VAL_ 2432656679 pOperatorButton22 0 "Not Pressed" 1 "Pressed" 2 "Error" 3 "Not Available" ;
VAL_ 2432656679 pOperatorButton23 0 "Not Pressed" 1 "Pressed" 2 "Error" 3 "Not Available" ;
VAL_ 2432656679 pOperatorButton24 0 "Not Pressed" 1 "Pressed" 2 "Error" 3 "Not Available" ;
VAL_ 2432656679 pOperatorButton25 0 "Not Pressed" 1 "Pressed" 2 "Error" 3 "Not Available" ;
VAL_ 2432656679 pOperatorButton26 0 "Not Pressed" 1 "Pressed" 2 "Error" 3 "Not Available" ;
VAL_ 2432656679 pOperatorButton27 0 "Not Pressed" 1 "Pressed" 2 "Error" 3 "Not Available" ;
VAL_ 2432656679 pOperatorButton28 0 "Not Pressed" 1 "Pressed" 2 "Error" 3 "Not Available" ;
VAL_ 2432656679 pSideStandStatus 3 "Not Available" 2 "Error Indicator" 1 "Side Stand Up" 0 "Side Stand Down" ;
VAL_ 2550791719 StaticRollAngleStatus 0 "Sensor Busy" 1 "Sensor OK" 2 "Sensor Defect" 3 "Sensor Reboots" 4 "Angle Data Invalid" 5 "Reserved" 6 "Error" 7 "Not Available" ;
VAL_ 2365473278 LowBeamHeadlightCommand 3 "Don't Care" 2 "Reserved" 1 "Activate" 0 "De-activate" ;
VAL_ 2365473278 HighBeamHeadlightCommand 3 "Don't Care" 2 "Reserved" 1 "Activate" 0 "De-activate" ;
VAL_ 2365473278 LeftTurnSigLightsCommand 0 "De-activate" 1 "Activate" 2 "Reserved" 3 "Don't Care" ;
VAL_ 2365473278 RightTurnSigLightsCommand 0 "De-activate" 1 "Activate" 2 "Reserved" 3 "Don't Care" ;
VAL_ 2631859966 TripGroup1 0 "Take no action" 1 "Reset" 3 "Not applicable" ;
VAL_ 2631859966 TripGroup2 0 "Take no action" 1 "Reset" 3 "Not applicable" ;
VAL_ 2631859966 EngineBuildHoursReset 0 "Do not reset" 1 "Reset" 3 "Take no action" ;
VAL_ 2566884606 BrakeSwitch 0 "PedalReleased" 1 "PedalDepressed" 2 "Error" 3 "NotAvailable" ;
VAL_ 2566878847 pHeadset2ConnectionStatus 3 "Not Available" 2 "Error" 1 "Headset Connected" 0 "Headset Not Connected" ;
VAL_ 2566878847 pHeadset1ConnectionStatus 3 "Not Available" 2 "Error" 1 "Headset Connected" 0 "Headset Not Connected" ;
VAL_ 2566878847 pDevice2CellSigStrength 7 "Not Available" 6 "Error" 5 "5 Bars of Cell Signal" 4 "4 Bars of Cell Signal" 3 "3 Bars of Cell Signal" 2 "2 Bars of Cell Signal" 1 "1 Bars of Cell Signal" 0 "0 Bars of Cell Signal" ;
VAL_ 2566878847 pDevice2BTConnectStatus 3 "Not Available" 2 "Error" 1 "Device Connected" 0 "Device Not Connected" ;
VAL_ 2566878847 pDevice2BattStrength 7 "Not Available" 6 "Error" 5 "5 Bars of Battery Strength" 4 "4 Bars of Battery Strength" 3 "3 Bars of Battery Strength" 2 "2 Bars of Battery Strength" 1 "1 Bars of Battery Strength" 0 "0 Bars of Battery Strength" ;
VAL_ 2566878847 pDevice1CellSigStrength 7 "Not Available" 6 "Error" 5 "5 Bars of Cell Signal" 4 "4 Bars of Cell Signal" 3 "3 Bars of Cell Signal" 2 "2 Bars of Cell Signal" 1 "1 Bars of Cell Signal" 0 "0 Bars of Cell Signal" ;
VAL_ 2566878847 pDevice1BTConnectStatus 3 "Not Available" 2 "Error" 1 "Device Connected" 0 "Device Not Connected" ;
VAL_ 2566878847 pDevice1BattStrength 7 "Not Available" 6 "Error" 5 "5 Bars of Battery Strength" 4 "4 Bars of Battery Strength" 3 "3 Bars of Battery Strength" 2 "2 Bars of Battery Strength" 1 "1 Bars of Battery Strength" 0 "0 Bars of Battery Strength" ;
VAL_ 2566877505 pVolumeUnitsSelected 7 "Not Available" 6 "Error" 5 "Reserved" 4 "Reserved" 3 "Reserved" 2 "Imperial Gallons" 1 "Liters" 0 "Gallons" ;
VAL_ 2566877505 pTimeUnitsSelected 3 "Not Available" 2 "Error" 1 "24 Hour" 0 "12 Hour" ;
VAL_ 2566877505 pTemperatureUnitsSelected 3 "Not Avaialable" 2 "Error" 1 "Celsius" 0 "Farenheit" ;
VAL_ 2566877505 pPressureUnitsSelected 3 "Not Available" 2 "Error" 1 "Kilopascal (kPa)" 0 "Pounds Per Square Inch (PSI)" ;
VAL_ 2566877505 pDistanceUnitsSelected 3 "Not Available" 2 "Error" 1 "Kilometers" 0 "Miles" ;
VAL_ 2566877505 pTPMSLearningStatus 0 "Not Started" 1 "Request to start" 2 "Learning Left Front" 3 "Learning Right Front" 4 "Learning Left Rear" 5 "Learning Right Rear" 6 "Learning successfully completed" 13 "Request to end learning" 14 "Error - Failed Learning" 15 "Not Available" ;
VAL_ 2566877505 pDisplayStatus 0 "Info cant overide to full screen" 1 "User requested full screen" 2 "Info can overide to full screen" 14 "Info data is not shown" 15 "Not Available" ;
VAL_ 2566877311 pHighlightRow 15 "Not Avialable" 14 "Error" 13 "Row 13 Highlighted" 12 "Row 12 Highlighted" 11 "Row 11 Highlighted" 10 "Row 10 Highlighted" 9 "Row 9 Highlighted" 8 "Row 8 Highlighted" 7 "Row 7 Highlighted" 6 "Row 6 Highlighted" 5 "Row 5 Highlighted" 4 "Row 4 Highlighted" 3 "Row 3 Highlighted" 2 "Row 2 Highlighted" 1 "Row 1 Highlighted" 0 "No Row Highlighted" ;
VAL_ 2566877311 pScreenAreaMode 7 "Not_Available" 6 "Error" 5 "Reserved" 4 "Reserved" 3 "Reserved" 2 "Reserved" 1 "Sending_Data_List" 0 "Normal_Screen_Dsiplay" ;
VAL_ 2566877311 pRadioInputDevice 0 "Blank" 1 "iPod" 2 "XM" 3 "AUX" 4 "USB" 5 "NAV" 6 "MP3" 7 "BLUETOOTH" 8 "PANDORA" 9 "SIRIUS" 10 "FM" 11 "FM1" 12 "FM2" 13 "FM3" 14 "FM4" 15 "WX" 16 "AM" 17 "LW" 18 "MW" 19 "SW" 20 "iHEART" 21 "ICOM" 22 "GMRS" 23 "CB" 24 "GMRS TX" 25 "GMRS RX" 31 "P1" 32 "P2" 33 "P3" 34 "P4" 35 "P5" 36 "P6" 37 "P7" 38 "P8" 39 "P9" 40 "P10" 41 "P11" 42 "P12" 43 "P13" 44 "P14" 45 "P15" 46 "P16" 47 "P17" 48 "P18" 49 "P19" 50 "P20" 61 "TURN LEFT" 62 "TURN RIGHT" 63 "DESTINATION" 70 "BT VOL" 71 "BT VOL+" 72 "BT VOL-" 80 "(THUMBS UP)" 81 "(THUMBS DOWN)" 91 "INCOMING CALL" 92 "INCOMING TEXT" 100 "RADIO OFF" 110 "BASS" 111 "TREBLE" 112 "MID" 113 "BALANCE" 114 "AVC" 115 "VOLUME" 116 "MUTE" 117 "FADE" 26 "Reserved" 255 "Not Available" ;
VAL_ 2566877311 pRadioScaling 0 "1/bit" 1 "0.1/bit - 1 decimal point" 2 "0.01/bit - 2 decimal points" 6 "Do not show Input value" 7 "Not Availalbe" ;
VAL_ 2566877311 pTextLineConfiguration 0 "No ASCII text shown" 1 "Standard 1 line of ASCII text" 2 "ASCII text control small area" 3 "ASCII text control large area" 7 "Not Available" ;
VAL_ 2566877311 pStereoStatus 0 "No Stereo" 1 "Stereo" 2 "Error" 3 "Not Available" ;
VAL_ 2566877311 pFirstRowConfiguration 6 "Error" 5 "Reserved" 4 "Reserved" 3 "Reserved" 0 "See Comment 0." 1 "See Comment 1." 2 "See Comment 2." 7 "Not Available" ;
VAL_ 2566877311 pScreenAreaConfiguration 0 "Normal Screen Size" 1 "Expanded Screen Size" 2 "Error" 3 "Not Available" ;
VAL_ 2432656449 pInfotainmentJoystick2 5 "Center" 4 "Right" 3 "Left" 2 "Down" 1 "Up" 0 "Neutral" ;
VAL_ 2432656449 pInfotainmentJoystick1 5 "Center" 4 "Right" 3 "Left" 2 "Down" 1 "Up" 0 "Neutral" ;
VAL_ 2432656449 pInfotainmentRemoteButton01 0 "Not Pressed" 1 "Pressed" 2 "Error" 3 "Not Available" ;
VAL_ 2432656449 pInfotainmentRemoteButton02 0 "Not Pressed" 1 "Pressed" 2 "Error" 3 "Not Available" ;
VAL_ 2432656449 pInfotainmentRemoteButton03 0 "Not Pressed" 1 "Pressed" 2 "Error" 3 "Not Available" ;
VAL_ 2432656449 pInfotainmentRemoteButton04 0 "Not Pressed" 1 "Pressed" 2 "Error" 3 "Not Available" ;
VAL_ 2432656449 pInfotainmentRemoteButton05 0 "Not Pressed" 1 "Pressed" 2 "Error" 3 "Not Available" ;
VAL_ 2432656449 pInfotainmentRemoteButton06 0 "Not Pressed" 1 "Pressed" 2 "Error" 3 "Not Available" ;
VAL_ 2432656449 pInfotainmentRemoteButton07 0 "Not Pressed" 1 "Pressed" 2 "Error" 3 "Not Available" ;
VAL_ 2432656449 pInfotainmentRemoteButton08 0 "Not Pressed" 1 "Pressed" 2 "Error" 3 "Not Available" ;
VAL_ 2432656449 pInfotainmentRemoteButton09 0 "Not Pressed" 1 "Pressed" 2 "Error" 3 "Not Available" ;
VAL_ 2432656449 pInfotainmentRemoteButton10 0 "Not Pressed" 1 "Pressed" 2 "Error" 3 "Not Available" ;
VAL_ 2432656449 pInfotainmentRemoteButton11 0 "Not Pressed" 1 "Pressed" 2 "Error" 3 "Not Available" ;
VAL_ 2432656449 pInfotainmentRemoteButton12 0 "Not Pressed" 1 "Pressed" 2 "Error" 3 "Not Available" ;
